VERSION ""

NS_ :

BS_:

BU_: CLU CGW BCW MDPS SCC AVM FCA ESC

BO_ 3221225472 VECTOR__INDEPENDENT_SIG_MSG: 0 Vector__XXX
 SG_ DIAG_RQST : 0|64@1+ (1,0) [0|0] "" Vector__XXX
 SG_ FUN_DIAG_RQST : 0|64@1+ (1,0) [0|0] "" Vector__XXX
 SG_ CF_SWL_Ind : 0|2@1+ (1,0) [0|3] "" Vector__XXX
 SG_ EPB_I_LAMP : 0|4@1+ (1,0) [0|15] "" Vector__XXX
 SG_ EPB_F_LAMP : 0|2@1+ (1,0) [0|3] "" Vector__XXX
 SG_ EPB_ALARM : 0|2@1+ (1,0) [0|3] "" Vector__XXX
 SG_ EPB_CLU : 0|8@1+ (1,0) [0|255] "" Vector__XXX
 SG_ CF_HDA_InfoDisplay : 0|3@1+ (1,0) [0|7] "" Vector__XXX
 SG_ CF_HDA_Mode : 0|2@1+ (1,0) [0|3] "" Vector__XXX
 SG_ CF_HDA_Opt_USM : 0|2@1+ (1,0) [0|3] "" Vector__XXX
 SG_ CF_HDA_AutoSetSpdUpdate : 0|1@1+ (1,0) [0|1] "" Vector__XXX
 SG_ CF_HDA_LFA_Wrn_Snd : 0|1@1+ (1,0) [0|1] "" Vector__XXX
 SG_ CF_HDA_LFA_SymbolState : 0|2@1+ (1,0) [0|3] "" Vector__XXX
 SG_ CF_LFA_Opt_USM : 0|2@1+ (1,0) [0|3] "" Vector__XXX
 SG_ AutoSetSpdEnable : 0|1@1+ (1,0) [0|1] "" Vector__XXX
 SG_ CF_LKA_LaneRecogState : 0|2@1+ (1,0) [0|3] "" Vector__XXX
 SG_ CF_LKA_SysState : 0|4@1+ (1,0) [0|15] "" Vector__XXX
 SG_ CF_LKA_SysWarning : 0|4@1+ (1,0) [0|15] "" Vector__XXX
 SG_ CF_LKA_LHWarning : 0|2@1+ (1,0) [0|3] "" Vector__XXX
 SG_ CF_LKA_RHWarning : 0|2@1+ (1,0) [0|3] "" Vector__XXX
 SG_ CF_HBA_Lamp : 0|1@1+ (1,0) [0|1] "" Vector__XXX
 SG_ CF_HBA_SysState : 0|3@1+ (1,0) [0|7] "" Vector__XXX
 SG_ CF_LKA_USM_Mode : 0|2@1+ (1,0) [0|3] "" Vector__XXX
 SG_ CF_LKA_SymbolState : 0|3@1+ (1,0) [0|7] "" Vector__XXX
 SG_ CF_LKA_Opt_USM : 0|3@1+ (1,0) [0|7] "" Vector__XXX
 SG_ CF_FCA_LO_Warning : 0|2@1+ (1,0) [0|3] "" Vector__XXX
 SG_ CF_HBA_Opt_USM : 0|2@1+ (1,0) [0|3] "" Vector__XXX
 SG_ CF_DAW_Status : 0|4@1+ (1,0) [0|15] "" Vector__XXX
 SG_ CF_DAW_TimeReset : 0|1@1+ (1,0) [0|1] "" Vector__XXX
 SG_ CF_DAW_Opt_USM_NEW : 0|2@1+ (1,0) [0|3] "" Vector__XXX
 SG_ CF_DAW_Warn : 0|2@1+ (1,0) [0|3] "" Vector__XXX
 SG_ CF_LeadVehDptAlert_Display : 0|2@1+ (1,0) [0|3] "" Vector__XXX
 SG_ CF_ISLW_Opt_USM : 0|2@1+ (1,0) [0|3] "" Vector__XXX
 SG_ CF_LeadVehDptAlert_USM : 0|2@1+ (1,0) [0|3] "" Vector__XXX
 SG_ POS_FL_W_LAMP : 0|1@1+ (1,0) [0|1] "" Vector__XXX
 SG_ POS_FR_W_LAMP : 0|1@1+ (1,0) [0|1] "" Vector__XXX
 SG_ POS_RL_W_LAMP : 0|1@1+ (1,0) [0|1] "" Vector__XXX
 SG_ POS_RR_W_LAMP : 0|1@1+ (1,0) [0|1] "" Vector__XXX
 SG_ STATUS_TPMS : 0|3@1+ (1,0) [0|7] "" Vector__XXX
 SG_ UNIT : 0|2@1+ (1,0) [0|3] "" Vector__XXX
 SG_ PRESSURE_FL : 0|8@1+ (1,0) [0|255] "" Vector__XXX
 SG_ PRESSURE_FR : 0|8@1+ (1,0) [0|255] "" Vector__XXX
 SG_ PRESSURE_RL : 0|8@1+ (1,0) [0|255] "" Vector__XXX
 SG_ PRESSURE_RR : 0|8@1+ (1,0) [0|255] "" Vector__XXX
 SG_ TPMS_W_LAMP : 0|2@1+ (1,0) [0|3] "" Vector__XXX
 SG_ TREAD_W_LAMP : 0|2@1+ (1,0) [0|3] "" Vector__XXX

BO_ 1998 DIAG_RSP: 8 CLU
 SG_ DIAG_RSP : 0|64@1+ (1,0) [0|0] "" Vector__XXX

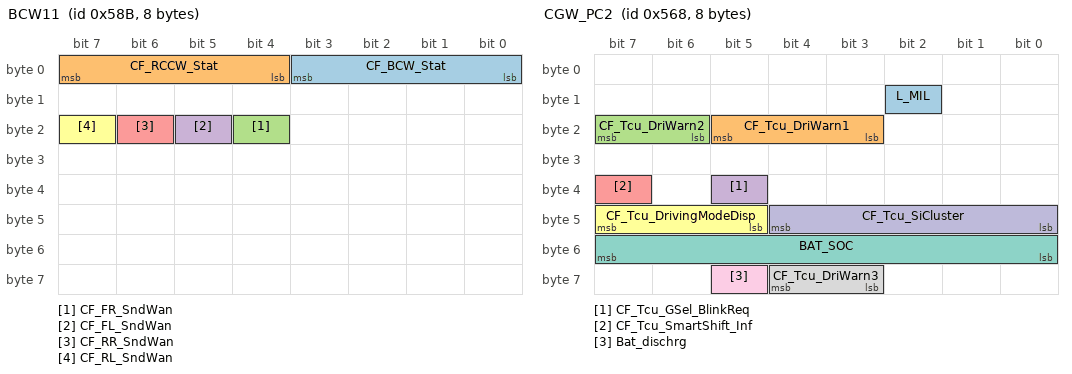
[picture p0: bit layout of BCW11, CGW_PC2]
BO_ 1419 BCW11: 8 BCW
 SG_ CF_BCW_Stat : 0|4@1+ (1,0) [0|15] ""  CGW,CLU
 SG_ CF_RCCW_Stat : 4|4@1+ (1,0) [0|15] ""  CGW,CLU
 SG_ CF_FR_SndWan : 20|1@1+ (1,0) [0|1] ""  CGW,CLU
 SG_ CF_FL_SndWan : 21|1@1+ (1,0) [0|1] ""  CGW,CLU
 SG_ CF_RR_SndWan : 22|1@1+ (1,0) [0|1] ""  CGW,CLU
 SG_ CF_RL_SndWan : 23|1@1+ (1,0) [0|1] ""  CGW,CLU

BO_ 1164 BCW12: 8 BCW
 SG_ CF_BCW_DrvSetState : 5|3@1+ (1,0) [0|7] ""  CGW,CLU

BO_ 1107 CGW_PC1: 5 CGW
 SG_ CR_Fatc_OutTempSns : 16|8@1+ (0.5,0) [-40|60] ""  CLU
 SG_ CR_Fatc_OutTemp : 8|8@1+ (0.5,0) [-40|60] ""  CLU

BO_ 1384 CGW_PC2: 8 CGW
 SG_ L_MIL : 10|1@1+ (1,0) [0|1] ""  CLU
 SG_ CF_Tcu_DriWarn1 : 19|3@1+ (1,0) [0|7] ""  CLU
 SG_ CF_Tcu_DriWarn2 : 22|2@1+ (1,0) [0|3] ""  CLU
 SG_ CF_Tcu_GSel_BlinkReq : 37|1@1+ (1,0) [0|1] ""  CLU
 SG_ CF_Tcu_SmartShift_Inf : 39|1@1+ (1,0) [0|1] ""  CLU
 SG_ CF_Tcu_DrivingModeDisp : 45|3@1+ (1,0) [0|7] ""  CLU
 SG_ BAT_SOC : 48|8@1+ (1,0) [0|100] ""  CLU
 SG_ CF_Tcu_DriWarn3 : 59|2@1+ (1,0) [0|3] ""  CLU
 SG_ Bat_dischrg : 61|1@1+ (1,0) [0|1] ""  CLU
 SG_ CF_Tcu_SiCluster : 40|5@1+ (1,0) [0|31] ""  CLU

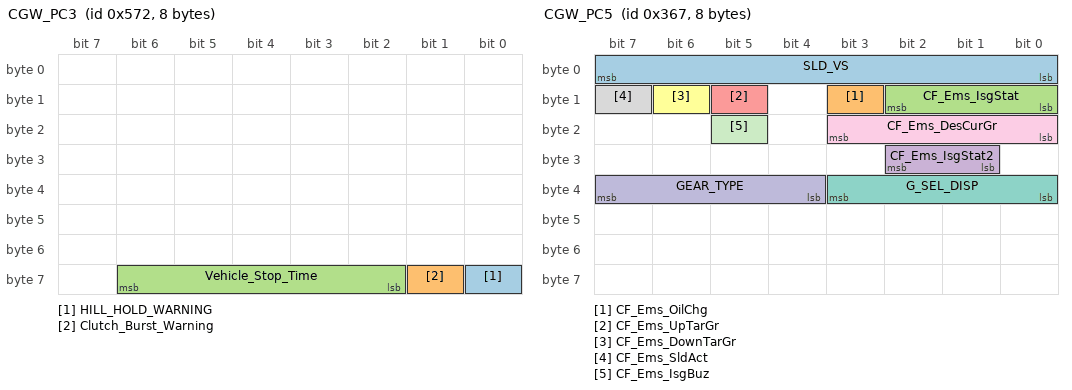
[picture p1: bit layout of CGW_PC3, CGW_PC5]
BO_ 1394 CGW_PC3: 8 CGW
 SG_ HILL_HOLD_WARNING : 56|1@1+ (1,0) [0|1] ""  CLU
 SG_ Clutch_Burst_Warning : 57|1@1+ (1,0) [0|1] ""  CLU
 SG_ Vehicle_Stop_Time : 58|5@1+ (1,0) [0|0] ""  CLU

BO_ 870 CGW_PC4: 7 CGW
 SG_ N : 8|16@1+ (0.25,0) [0|16383.75] ""  CLU
 SG_ F_N_ENG : 49|1@1+ (1,0) [0|1] ""  CLU

BO_ 871 CGW_PC5: 8 CGW
 SG_ SLD_VS : 0|8@1+ (1,0) [0|255] ""  CLU
 SG_ CF_Ems_OilChg : 11|1@1+ (1,0) [0|1] ""  CLU
 SG_ CF_Ems_IsgStat : 8|3@1+ (1,0) [0|7] ""  CLU,MDPS,SCC
 SG_ CF_Ems_IsgStat2 : 25|2@1+ (2,0) [0|3] ""  CLU
 SG_ CF_Ems_UpTarGr : 13|1@1+ (1,0) [0|1] ""  CLU
 SG_ CF_Ems_DownTarGr : 14|1@1+ (1,0) [0|1] ""  CLU
 SG_ G_SEL_DISP : 32|4@1+ (1,0) [0|15] ""  AVM,BCW,CLU,FCA,MDPS,SCC
 SG_ CF_Ems_SldAct : 15|1@1+ (1,0) [0|1] ""  CLU,SCC
 SG_ CF_Ems_DesCurGr : 16|4@1+ (1,0) [0|15] ""  CLU
 SG_ GEAR_TYPE : 36|4@1+ (1,0) [0|15] ""  CLU
 SG_ CF_Ems_IsgBuz : 21|1@1+ (1,0) [0|1] ""  CLU

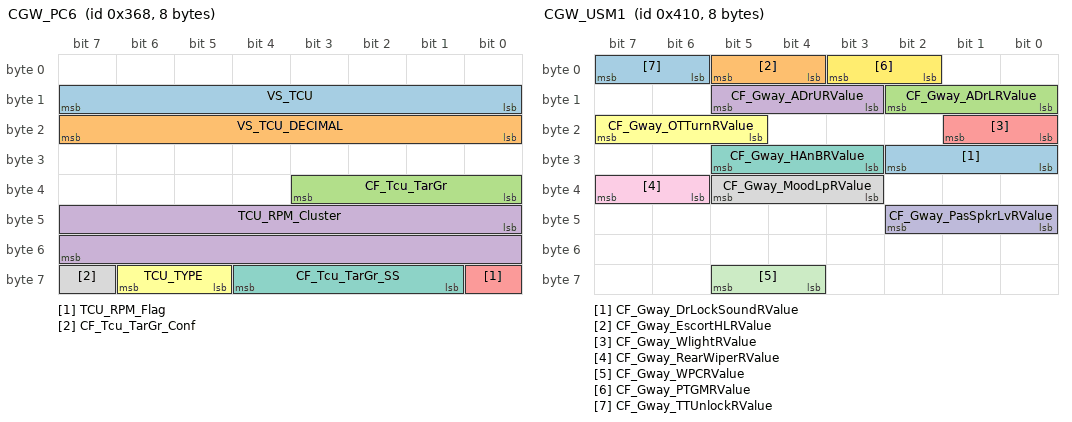
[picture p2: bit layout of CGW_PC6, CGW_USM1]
BO_ 872 CGW_PC6: 8 CGW
 SG_ VS_TCU : 8|8@1+ (1,0) [0|254] ""  CLU
 SG_ VS_TCU_DECIMAL : 16|8@1+ (0.0078125,0) [0|0.9921875] ""  CLU
 SG_ CF_Tcu_TarGr : 32|4@1+ (1,0) [0|15] ""  CLU
 SG_ TCU_RPM_Cluster : 40|16@1+ (0.25,0) [0|16383.5] ""  CLU
 SG_ TCU_RPM_Flag : 56|1@1+ (1,0) [0|0] ""  CLU
 SG_ TCU_TYPE : 61|2@1+ (1,0) [0|3] ""  CLU
 SG_ CF_Tcu_TarGr_SS : 57|4@1+ (1,0) [0|15] ""  CLU
 SG_ CF_Tcu_TarGr_Conf : 63|1@1+ (1,0) [0|0] ""  CLU

BO_ 854 CGW_PC8: 7 CGW
 SG_ FCO : 32|16@1+ (0.128,0) [0|8388.48] ""  CLU

BO_ 576 CGW_PC11: 8 CGW
 SG_ G_SEL_DISP_eClutch : 12|4@1+ (1,0) [0|15] ""  AVM,BCW,CGW,CLU,FCA,MDPS,SCC

BO_ 1225 CGW_PC12: 8 CGW
 SG_ CF_TCU_AvgCltTemp : 0|4@1+ (1,0) [0|15] ""  CLU

BO_ 1040 CGW_USM1: 8 CGW
 SG_ CF_Gway_DrLockSoundRValue : 24|3@1+ (1,0) [0|3] ""  CLU
 SG_ CF_Gway_EscortHLRValue : 4|2@1+ (1,0) [0|3] ""  CLU
 SG_ CF_Gway_ADrLRValue : 8|3@1+ (1,0) [0|7] ""  CLU
 SG_ CF_Gway_ADrURValue : 11|3@1+ (1,0) [0|7] ""  CLU
 SG_ CF_Gway_WlightRValue : 16|2@1+ (1,0) [0|3] ""  CLU
 SG_ CF_Gway_OTTurnRValue : 21|3@1+ (1,0) [0|7] ""  CLU
 SG_ CF_Gway_HAnBRValue : 27|3@1+ (1,0) [0|7] ""  CLU
 SG_ CF_Gway_MoodLpRValue : 35|3@1+ (1,0) [0|7] ""  CLU
 SG_ CF_Gway_RearWiperRValue : 38|2@1+ (1,0) [0|3] ""  CLU
 SG_ CF_Gway_PasSpkrLvRValue : 40|3@1+ (1,0) [0|7] ""  CLU
 SG_ CF_Gway_WPCRValue : 60|2@1+ (1,0) [0|3] ""  CLU
 SG_ CF_Gway_PTGMRValue : 2|2@1+ (1,0) [0|3] ""  CLU
 SG_ CF_Gway_TTUnlockRValue : 6|2@1+ (1,0) [0|3] ""  CLU

BO_ 1042 CGW_USM2: 8 CGW
 SG_ CF_Gway_AFoldRValue : 0|2@1+ (1,0) [0|3] ""  CLU
 SG_ CF_Gway_WALRValue : 46|2@1+ (1,0) [0|3] ""  CLU

BO_ 1345 CGW1: 8 CGW
 SG_ CF_Gway_IGNSw : 0|3@1+ (1,0) [0|7] ""  CLU
 SG_ CF_Gway_RKECmd : 3|3@1+ (1,0) [0|7] ""  CLU
 SG_ CF_Gway_DrvDrSw : 8|2@1+ (1,0) [0|3] ""  CLU
 SG_ CF_Gway_TrunkTgSw : 12|2@1+ (1,0) [0|3] ""  CLU
 SG_ CF_Gway_SMKOption : 16|1@1+ (1,0) [0|1] ""  CLU
 SG_ CF_Gway_HoodSw : 17|2@1+ (1,0) [0|3] ""  CLU
 SG_ CF_Gway_TurnSigLh : 19|2@1+ (1,0) [0|3] ""  CLU
 SG_ CF_Gway_WiperIntT : 21|3@1+ (1,0) [0|7] ""  CLU
 SG_ CF_Gway_HeadLampLow : 31|1@1+ (1,0) [0|1] ""  CLU
 SG_ CF_Gway_HeadLampHigh : 32|1@1+ (1,0) [0|1] ""  CLU
 SG_ CF_Gway_AstDrSw : 35|1@1+ (1,0) [0|1] ""  CLU
 SG_ CF_Gway_LightSwState : 38|2@1+ (1,0) [0|3] ""  CLU
 SG_ CF_Gway_Frt_Fog_Act : 40|1@1+ (1,0) [0|1] ""  CLU
 SG_ CF_Gway_DriveTypeOption : 43|1@1+ (1,0) [0|1] ""  CLU
 SG_ CF_Gway_PassiveAccessLock : 45|2@1+ (1,0) [0|7] ""  CLU
 SG_ CF_Gway_PassiveAccessUnlock : 48|2@1+ (1,0) [0|7] ""  CLU
 SG_ CF_Gway_InhibitRMT : 54|2@1+ (1,0) [0|3] ""  CLU
 SG_ CF_Gway_RainSnsOption : 56|1@1+ (1,0) [0|1] ""  CLU
 SG_ C_SunRoofOpenState : 57|1@1+ (1,0) [0|1] ""  CLU
 SG_ CF_Gway_ParkBrakeSw : 60|2@1+ (1,0) [0|3] ""  CLU
 SG_ CF_Gway_TurnSigRh : 62|2@1+ (1,0) [0|3] ""  CLU

BO_ 1363 CGW2: 8 CGW
 SG_ CF_Gway_ExtTailAct : 8|2@1+ (1,0) [0|3] ""  CLU
 SG_ CF_Gway_AutoLightValue : 16|1@1+ (1,0) [0|1] ""  CLU
 SG_ CF_Gway_BrakeFluidSw : 17|1@1+ (1,0) [0|1] ""  CLU
 SG_ CF_Gway_ICUPowerAutoCutMode : 18|2@1+ (1,0) [0|3] ""  CLU
 SG_ CF_Gway_AvTail : 20|1@1+ (1,0) [0|1] ""  CLU
 SG_ CF_Gway_RearFogAct : 21|1@1+ (1,0) [0|1] ""  CLU
 SG_ CF_Gway_RRDrSw : 23|1@1+ (1,0) [0|1] ""  CLU
 SG_ CF_Gway_RLDrSw : 24|1@1+ (1,0) [0|1] ""  CLU
 SG_ CF_Gway_ESCLFailWarn : 35|1@1+ (1,0) [0|1] ""  CLU
 SG_ CF_Gway_ESCLNotLockedWarn : 36|1@1+ (1,0) [0|1] ""  CLU
 SG_ CF_Gway_ESCLNotUnlockWarn : 37|1@1+ (1,0) [0|1] ""  CLU
 SG_ CF_Gway_IDoutWarn : 38|1@1+ (1,0) [0|1] ""  CLU
 SG_ CF_Gway_ImmoLp : 40|1@1+ (1,0) [0|3] ""  CLU
 SG_ CF_Gway_VehicleNotPWarn : 44|1@1+ (1,0) [0|1] ""  CLU
 SG_ CF_Gway_DeactivationWarn : 45|1@1+ (1,0) [0|1] ""  CLU
 SG_ CF_Gway_KeyBATDischargeWarn : 46|1@1+ (1,0) [0|1] ""  CLU
 SG_ CF_Gway_SSBWarn : 47|1@1+ (1,0) [0|1] ""  CLU
 SG_ CF_Gway_SMKRKECmd : 51|3@1+ (1,0) [0|7] ""  CLU
 SG_ CF_Gway_KeyoutLp : 56|1@1+ (1,0) [0|1] ""  CLU
 SG_ CF_Gway_SMKDispWarn : 57|4@1+ (1,0) [0|15] ""  CLU
 SG_ CF_Gway_WngBuz : 61|3@1+ (1,0) [0|7] ""  CLU

BO_ 1312 CGW3: 8 CGW
 SG_ CF_Gway_AccINDforCLU : 60|1@1+ (1,0) [0|1] ""  CLU

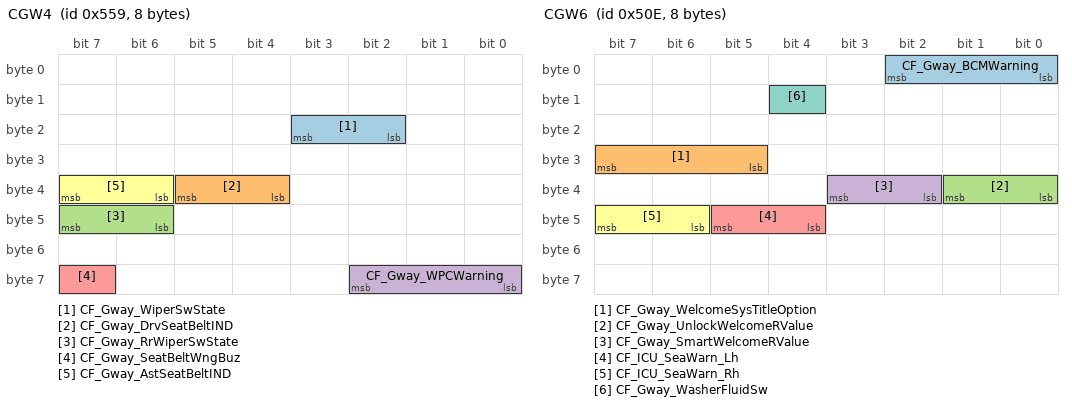
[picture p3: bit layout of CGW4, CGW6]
BO_ 1369 CGW4: 8 CGW
 SG_ CF_Gway_WiperSwState : 18|2@1+ (1,0) [0|3] ""  CLU
 SG_ CF_Gway_DrvSeatBeltIND : 36|2@1+ (1,0) [0|3] ""  CLU
 SG_ CF_Gway_RrWiperSwState : 46|2@1+ (1,0) [0|3] ""  CLU
 SG_ CF_Gway_WPCWarning : 56|3@1+ (1,0) [0|7] ""  CLU
 SG_ CF_Gway_SeatBeltWngBuz : 63|1@1+ (1,0) [0|1] ""  CLU
 SG_ CF_Gway_AstSeatBeltIND : 38|2@1+ (1,0) [0|3] ""  CLU

BO_ 127 CGW5: 8 CGW
 SG_ C_StopLampLhOpenSts : 0|1@1+ (1,0) [0|1] ""  CLU
 SG_ C_StopLampRhOpenSts : 1|1@1+ (1,0) [0|1] ""  CLU
 SG_ C_HMSLOpenSts : 2|1@1+ (1,0) [0|1] ""  CLU
 SG_ C_HLampLowLhOpenSts : 3|1@1+ (1,0) [0|1] ""  CLU
 SG_ C_HLampLowRhOpenSts : 4|1@1+ (1,0) [0|1] ""  CLU
 SG_ C_HLampHighLhOpenSts : 5|1@1+ (1,0) [0|1] ""  CLU
 SG_ C_HLampHighRhOpenSts : 6|1@1+ (1,0) [0|1] ""  CLU
 SG_ C_DRLLampLhOpenSts : 7|1@1+ (1,0) [0|1] ""  CLU
 SG_ C_DRLLampRhOpenSts : 8|1@1+ (1,0) [0|1] ""  CLU
 SG_ C_RearFOGLhOpenSts : 9|1@1+ (1,0) [0|1] ""  CLU
 SG_ C_RearFOGRhOpenSts : 10|1@1+ (1,0) [0|1] ""  CLU
 SG_ C_FrontFOGLhOpenSts : 11|1@1+ (1,0) [0|1] ""  CLU
 SG_ C_FrontFOGRhOpenSts : 12|1@1+ (1,0) [0|1] ""  CLU
 SG_ C_RearTSIGLhOpenSts : 17|1@1+ (1,0) [0|1] ""  CLU
 SG_ C_RearTSIGRhOpenSts : 18|1@1+ (1,0) [0|1] ""  CLU
 SG_ C_FrontTSIGLhOpenSts : 19|1@1+ (1,0) [0|1] ""  CLU
 SG_ C_FrontTSIGRhOpenSts : 20|1@1+ (1,0) [0|1] ""  CLU
 SG_ C_SBendingLhOpenSts : 21|1@1+ (1,0) [0|1] ""  CLU
 SG_ C_SBendingRhOpenSts : 22|1@1+ (1,0) [0|1] ""  CLU
 SG_ C_HLampBifuncLhOpenSts : 25|1@1+ (1,0) [0|1] ""  CLU
 SG_ C_HLampBifuncRhOpenSts : 26|1@1+ (1,0) [0|1] ""  CLU
 SG_ CF_Afs_LedHLStat : 30|2@1+ (1,0) [0|3] ""  CLU
 SG_ C_FrontEXTTailLhOpenSts : 15|1@1+ (1,0) [0|1] ""  CLU
 SG_ C_FrontEXTTailRhOpenSts : 16|1@1+ (1,0) [0|1] ""  CLU
 SG_ C_RearEXTTailLhOpenSts : 13|1@1+ (1,0) [0|1] ""  CLU
 SG_ C_RearEXTTailRhOpenSts : 14|1@1+ (1,0) [0|1] ""  CLU
 SG_ C_LicensePlateLhOpenSts : 23|1@1+ (1,0) [0|1] ""  CLU
 SG_ C_LicensePlateRhOpenSts : 24|1@1+ (1,0) [0|1] ""  CLU
 SG_ C_FrontFOGCorneringLpRhOpenSts : 28|1@1+ (1,0) [0|1] ""  CLU
 SG_ C_FrontFOGCorneringLpLhOpenSts : 29|1@1+ (1,0) [0|1] ""  CLU
 SG_ CF_Gway_MoodLpColorRValue : 56|4@1+ (1,0) [0|15] ""  CLU
 SG_ CF_Gway_MoodLpBrightRValue : 60|3@1+ (1,0) [0|7] ""  CLU

BO_ 1294 CGW6: 8 CGW
 SG_ CF_Gway_BCMWarning : 0|3@1+ (1,0) [0|7] ""  CLU
 SG_ CF_Gway_WelcomeSysTitleOption : 29|3@1+ (1,0) [0|0] ""  CLU
 SG_ CF_Gway_UnlockWelcomeRValue : 32|2@1+ (1,0) [0|0] ""  CLU
 SG_ CF_Gway_SmartWelcomeRValue : 34|2@1+ (1,0) [0|0] ""  CLU
 SG_ CF_ICU_SeaWarn_Lh : 44|2@1+ (1,0) [0|0] ""  CLU
 SG_ CF_ICU_SeaWarn_Rh : 46|2@1+ (1,0) [0|0] ""  CLU
 SG_ CF_Gway_WasherFluidSw : 12|1@1+ (1,0) [0|1] ""  CLU

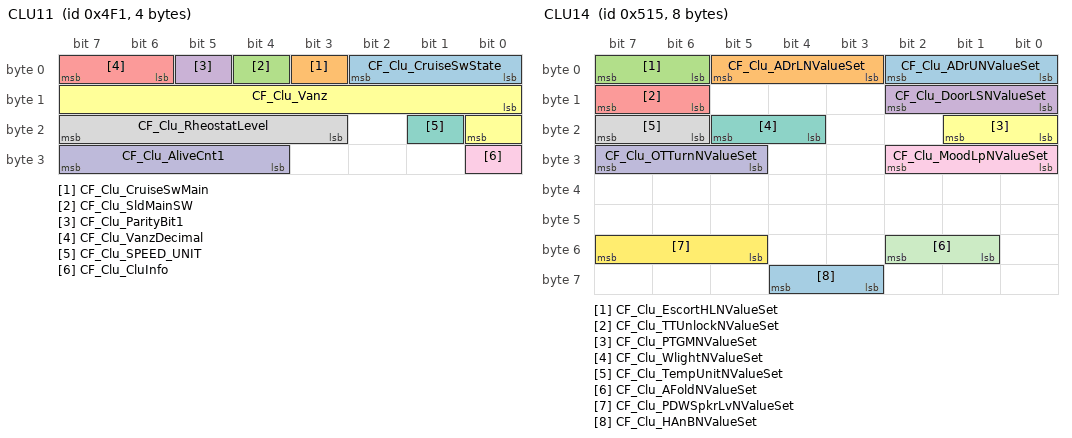
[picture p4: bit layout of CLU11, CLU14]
BO_ 1265 CLU11: 4 CLU
 SG_ CF_Clu_CruiseSwState : 0|3@1+ (1,0) [0|7] ""  CGW
 SG_ CF_Clu_CruiseSwMain : 3|1@1+ (1,0) [0|1] ""  CGW
 SG_ CF_Clu_SldMainSW : 4|1@1+ (1,0) [0|1] ""  CGW,SCC
 SG_ CF_Clu_ParityBit1 : 5|1@1+ (1,0) [0|1] ""  CGW
 SG_ CF_Clu_VanzDecimal : 6|2@1+ (0.125,0) [0|0.375] "" Vector__XXX
 SG_ CF_Clu_Vanz : 8|9@1+ (0.5,0) [0|255.5] ""  CGW
 SG_ CF_Clu_SPEED_UNIT : 17|1@1+ (1,0) [0|1] ""  CGW,ESC
 SG_ CF_Clu_RheostatLevel : 19|5@1+ (1,0) [0|31] ""  CGW
 SG_ CF_Clu_CluInfo : 24|1@1+ (1,0) [0|1] "" Vector__XXX
 SG_ CF_Clu_AliveCnt1 : 28|4@1+ (1,0) [0|15] ""  CGW

BO_ 1456 CLU12: 4 CLU
 SG_ CF_Clu_Odometer : 0|24@1+ (0.1,0) [0|1677721.4] ""  CGW

BO_ 1292 CLU13: 8 CLU
 SG_ CF_Clu_LowfuelWarn : 0|2@1+ (1,0) [0|3] ""  CGW
 SG_ CF_Clu_RefDetMod : 2|1@1+ (1,0) [0|1] ""  CGW
 SG_ CF_Clu_AvgFCU : 3|2@1+ (1,0) [0|3] "" Vector__XXX
 SG_ CF_Clu_AvgFCI : 6|10@1+ (0.1,0) [0|102.2] "" Vector__XXX
 SG_ CF_Clu_DrivingModeSwi : 16|2@1+ (1,0) [0|3] ""  CGW,ESC
 SG_ CF_Clu_TerrainModeSw : 18|3@1+ (1,0) [0|7] ""  CGW,ESC
 SG_ CF_Clu_GLOW_Stat : 21|2@1+ (1,0) [0|3] "" Vector__XXX
 SG_ CF_Clu_DTE : 24|10@1+ (1,0) [0|1023] ""  CGW
 SG_ CF_Clu_TripUnit : 34|2@1+ (1,0) [0|3] ""  CGW
 SG_ CF_Clu_SWL_Stat : 36|3@1+ (1,0) [0|7] "" Vector__XXX
 SG_ CF_Clu_DrivinglampStat : 44|3@1+ (1,0) [0|7] ""  CGW,ESC
 SG_ CF_Clu_RefuelWarn : 53|2@1+ (1,0) [0|3] "" Vector__XXX
 SG_ CF_Clu_IceWarnIndStat : 55|1@1+ (1,0) [0|1] "" Vector__XXX
 SG_ CF_Clu_ClusterUSM : 57|2@1+ (1,0) [0|0] ""  CGW
 SG_ CF_Clu_AltLStatus : 59|1@1+ (1,0) [0|1] "" Vector__XXX
 SG_ CF_Clu_AliveCnt2 : 60|4@1+ (1,0) [0|15] "" Vector__XXX
 SG_ CF_Clu_DAWLastBreakTime : 49|4@1+ (1,0) [0|15] ""  CGW

BO_ 1301 CLU14: 8 CLU
 SG_ CF_Clu_ADrUNValueSet : 0|3@1+ (1,0) [0|7] ""  CGW
 SG_ CF_Clu_ADrLNValueSet : 3|3@1+ (1,0) [0|7] ""  CGW
 SG_ CF_Clu_EscortHLNValueSet : 6|2@1+ (1,0) [0|3] ""  CGW
 SG_ CF_Clu_DoorLSNValueSet : 8|3@1+ (1,0) [0|7] "" Vector__XXX
 SG_ CF_Clu_TTUnlockNValueSet : 14|2@1+ (1,0) [0|3] "" Vector__XXX
 SG_ CF_Clu_PTGMNValueSet : 16|2@1+ (1,0) [0|3] "" Vector__XXX
 SG_ CF_Clu_WlightNValueSet : 20|2@1+ (1,0) [0|3] "" Vector__XXX
 SG_ CF_Clu_TempUnitNValueSet : 22|2@1+ (1,0) [0|3] ""  CGW
 SG_ CF_Clu_MoodLpNValueSet : 24|3@1+ (1,0) [0|7] ""  CGW
 SG_ CF_Clu_OTTurnNValueSet : 29|3@1+ (1,0) [0|7] ""  CGW
 SG_ CF_Clu_AFoldNValueSet : 49|2@1+ (1,0) [0|3] "" Vector__XXX
 SG_ CF_Clu_PDWSpkrLvNValueSet : 53|3@1+ (1,0) [0|7] ""  CGW
 SG_ CF_Clu_HAnBNValueSet : 59|2@1+ (1,0) [0|3] ""  CGW

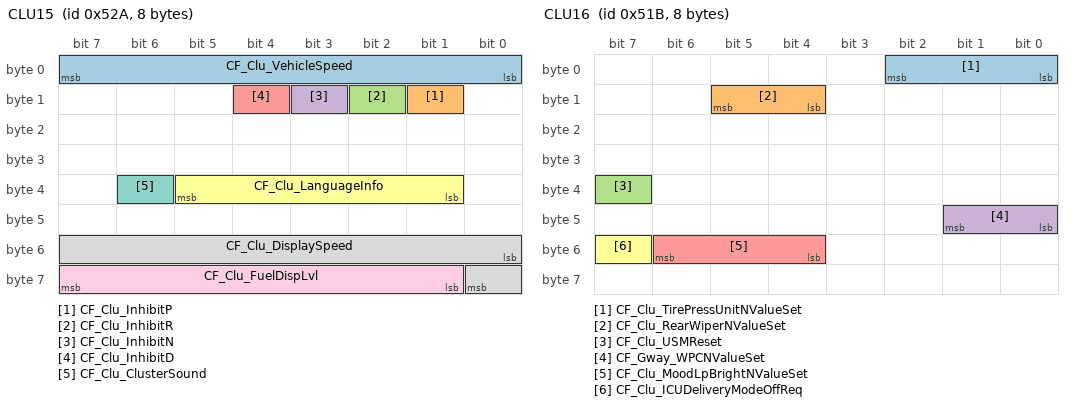
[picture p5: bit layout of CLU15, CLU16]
BO_ 1322 CLU15: 8 CLU
 SG_ CF_Clu_VehicleSpeed : 0|8@1+ (1,0) [0|254] ""  CGW
 SG_ CF_Clu_InhibitP : 9|1@1+ (1,0) [0|1] "" Vector__XXX
 SG_ CF_Clu_InhibitR : 10|1@1+ (1,0) [0|1] "" Vector__XXX
 SG_ CF_Clu_InhibitN : 11|1@1+ (1,0) [0|1] "" Vector__XXX
 SG_ CF_Clu_InhibitD : 12|1@1+ (1,0) [0|1] "" Vector__XXX
 SG_ CF_Clu_LanguageInfo : 33|5@1+ (1,0) [0|31] "" Vector__XXX
 SG_ CF_Clu_ClusterSound : 38|1@1- (1,0) [0|0] ""  CGW
 SG_ CF_Clu_DisplaySpeed : 48|9@1+ (1,0) [0|510] ""  CGW
 SG_ CF_Clu_FuelDispLvl : 57|7@1+ (1,0) [0|0] ""  CGW

BO_ 1307 CLU16: 8 CLU
 SG_ CF_Clu_TirePressUnitNValueSet : 0|3@1+ (1,0) [0|7] "" Vector__XXX
 SG_ CF_Clu_RearWiperNValueSet : 12|2@1+ (1,0) [0|3] ""  CGW
 SG_ CF_Clu_USMReset : 39|1@1+ (1,0) [0|1] ""  CGW
 SG_ CF_Gway_WPCNValueSet : 40|2@1+ (1,0) [0|3] ""  CGW
 SG_ CF_Clu_MoodLpBrightNValueSet : 52|3@1+ (1,0) [0|7] ""  CGW
 SG_ CF_Clu_ICUDeliveryModeOffReq : 55|1@1+ (1,0) [0|1] ""  CGW

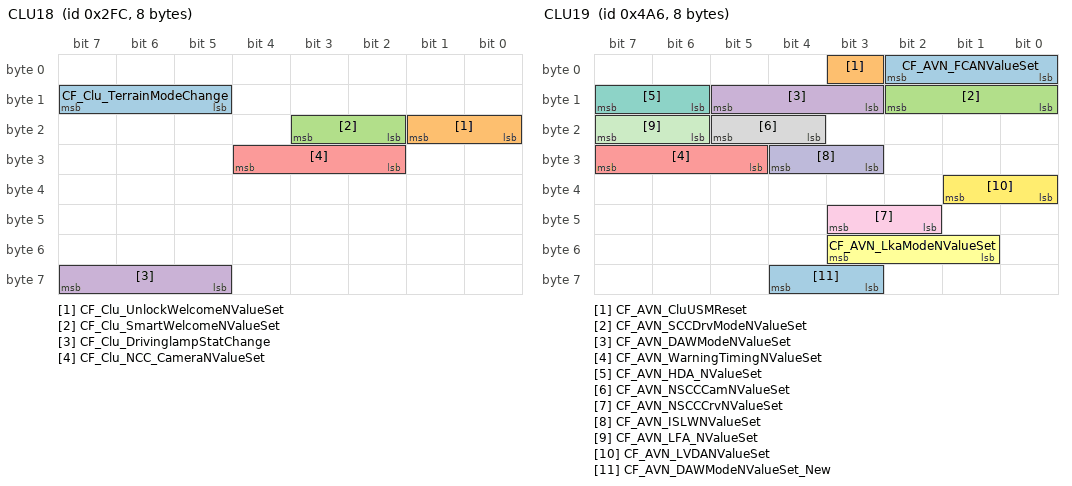
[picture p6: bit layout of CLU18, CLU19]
BO_ 764 CLU18: 8 CLU
 SG_ CF_Clu_TerrainModeChange : 13|3@1+ (1,0) [0|7] ""  CGW
 SG_ CF_Clu_UnlockWelcomeNValueSet : 16|2@1+ (1,0) [0|3] ""  CGW
 SG_ CF_Clu_SmartWelcomeNValueSet : 18|2@1+ (1,0) [0|3] ""  CGW
 SG_ CF_Clu_DrivinglampStatChange : 61|3@1+ (1,0) [0|7] ""  CGW
 SG_ CF_Clu_NCC_CameraNValueSet : 26|3@1+ (1,0) [0|7] ""  CGW

BO_ 1190 CLU19: 8 CLU
 SG_ CF_AVN_FCANValueSet : 0|3@1+ (1,0) [0|7] "" Vector__XXX
 SG_ CF_AVN_CluUSMReset : 3|1@1+ (1,0) [0|1] "" Vector__XXX
 SG_ CF_AVN_SCCDrvModeNValueSet : 8|3@1+ (1,0) [0|7] "" Vector__XXX
 SG_ CF_AVN_DAWModeNValueSet : 11|3@1+ (1,0) [0|7] "" Vector__XXX
 SG_ CF_AVN_WarningTimingNValueSet : 29|3@1+ (1,0) [0|7] "" Vector__XXX
 SG_ CF_AVN_LkaModeNValueSet : 49|3@1+ (1,0) [0|7] "" Vector__XXX
 SG_ CF_AVN_HDA_NValueSet : 14|2@1+ (1,0) [0|3] "" Vector__XXX
 SG_ CF_AVN_NSCCCamNValueSet : 20|2@1+ (1,0) [0|3] ""  SCC
 SG_ CF_AVN_NSCCCrvNValueSet : 42|2@1+ (1,0) [0|3] ""  SCC
 SG_ CF_AVN_ISLWNValueSet : 27|2@1+ (1,0) [0|3] "" Vector__XXX
 SG_ CF_AVN_LFA_NValueSet : 22|2@1+ (1,0) [0|3] "" Vector__XXX
 SG_ CF_AVN_LVDANValueSet : 32|2@1+ (1,0) [0|3] ""  SCC
 SG_ CF_AVN_DAWModeNValueSet_New : 59|2@1+ (1,0) [0|3] "" Vector__XXX

BO_ 1158 CLU20: 8 CLU
 SG_ CF_Clu_WALNValueSet : 58|2@1+ (1,0) [0|3] "" Vector__XXX

BO_ 913 CLU21: 8 CLU
 SG_ CF_Clu_PaddUpSwState : 0|1@1+ (1,0) [0|1] "" Vector__XXX
 SG_ CF_Clu_PaddDownSwState : 1|1@1+ (1,0) [0|1] "" Vector__XXX

BO_ 68 DATC11: 8 CGW
 SG_ CR_Datc_OutTempC : 24|8@1+ (0.5,0) [-41|86.5] ""  CLU
 SG_ CR_Datc_OutTempF : 32|8@1+ (1,0) [-42|213] ""  CLU

BO_ 67 DATC13: 8 CGW
 SG_ CF_Datc_TempDispUnit : 0|2@1+ (1,0) [0|3] ""  CLU

BO_ 809 EMS12: 8 CGW
 SG_ TEMP_ENG : 8|8@1+ (0.75,0) [-48|143.25] ""  CLU

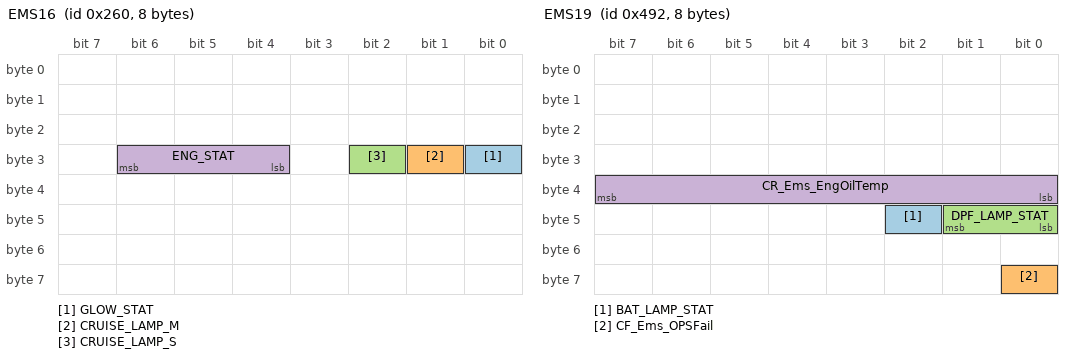
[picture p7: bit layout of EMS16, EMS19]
BO_ 608 EMS16: 8 CGW
 SG_ GLOW_STAT : 24|1@1+ (1,0) [0|1] ""  CLU
 SG_ CRUISE_LAMP_M : 25|1@1+ (1,0) [0|1] ""  CLU
 SG_ CRUISE_LAMP_S : 26|1@1+ (1,0) [0|1] ""  CLU
 SG_ ENG_STAT : 28|3@1+ (1,0) [0|7] ""  CLU,MDPS

BO_ 1170 EMS19: 8 CGW
 SG_ BAT_LAMP_STAT : 42|1@1+ (1,0) [0|1] ""  CLU
 SG_ CF_Ems_OPSFail : 56|1@1+ (1,0) [0|1] ""  CLU
 SG_ DPF_LAMP_STAT : 40|2@1+ (1,0) [0|3] ""  CLU
 SG_ CR_Ems_EngOilTemp : 32|8@1+ (0.75,0) [0|254] ""  CLU

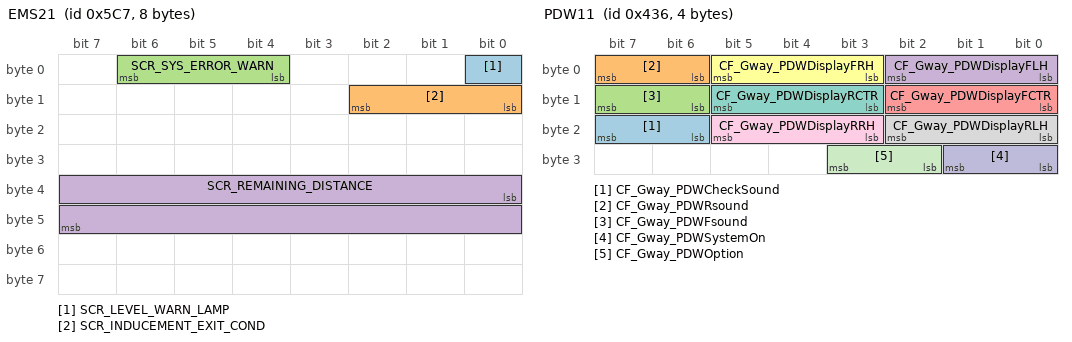
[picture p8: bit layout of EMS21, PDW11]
BO_ 1479 EMS21: 8 CGW
 SG_ SCR_LEVEL_WARN_LAMP : 0|1@1+ (1,0) [0|1] ""  CLU
 SG_ SCR_INDUCEMENT_EXIT_COND : 8|3@1+ (1,0) [0|7] ""  CLU
 SG_ SCR_SYS_ERROR_WARN : 4|3@1+ (1,0) [0|7] ""  CLU
 SG_ SCR_REMAINING_DISTANCE : 32|16@1+ (1,0) [0|25000] ""  CLU

BO_ 1155 FCA12: 8 FCA
 SG_ FCA_DrvSetState : 3|3@1+ (1,0) [0|7] ""  CGW,CLU
 SG_ FCA_USM : 0|3@1+ (1,0) [0|7] ""  CGW,CLU

BO_ 897 MDPS11: 8 MDPS
 SG_ CF_Mdps_WLmp : 0|2@1+ (1,0) [0|3] ""  CGW,CLU,ESC

BO_ 1078 PDW11: 4 CGW
 SG_ CF_Gway_PDWCheckSound : 22|2@1+ (1,0) [0|3] ""  CLU
 SG_ CF_Gway_PDWRsound : 6|2@1+ (1,0) [0|3] ""  CLU
 SG_ CF_Gway_PDWFsound : 14|2@1+ (1,0) [0|3] ""  CLU
 SG_ CF_Gway_PDWDisplayFLH : 0|3@1+ (1,0) [0|7] ""  AVM,CLU
 SG_ CF_Gway_PDWDisplayFCTR : 8|3@1+ (1,0) [0|7] ""  AVM,CLU
 SG_ CF_Gway_PDWDisplayFRH : 3|3@1+ (1,0) [0|7] ""  AVM,CLU
 SG_ CF_Gway_PDWDisplayRCTR : 11|3@1+ (1,0) [0|7] ""  AVM,CLU
 SG_ CF_Gway_PDWDisplayRLH : 16|3@1+ (1,0) [0|7] ""  AVM,CLU
 SG_ CF_Gway_PDWDisplayRRH : 19|3@1+ (1,0) [0|7] ""  AVM,CLU
 SG_ CF_Gway_PDWSystemOn : 24|2@1+ (1,0) [0|3] ""  BCW,CLU
 SG_ CF_Gway_PDWOption : 26|2@1+ (1,0) [0|3] ""  CLU

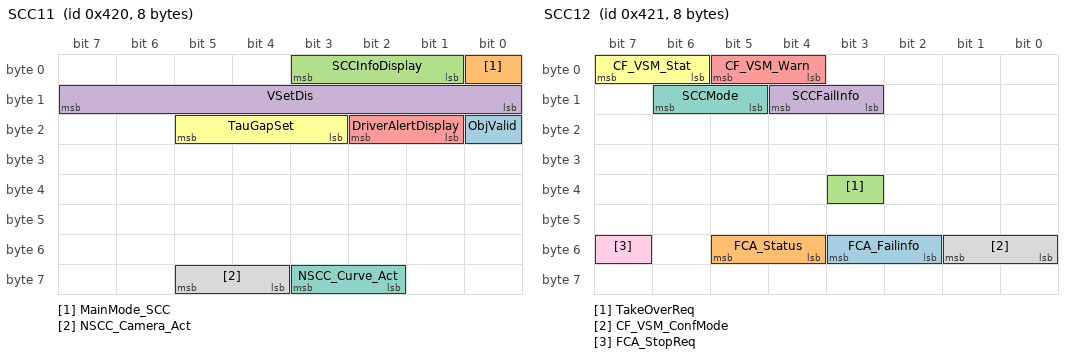
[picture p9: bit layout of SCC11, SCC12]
BO_ 1056 SCC11: 8 SCC
 SG_ ObjValid : 16|1@1+ (1,0) [0|1] ""  CGW,CLU,ESC
 SG_ MainMode_SCC : 0|1@1+ (1,0) [0|1] ""  CGW,CLU,ESC
 SG_ SCCInfoDisplay : 1|3@1+ (1,0) [0|7] ""  CGW,CLU,ESC
 SG_ VSetDis : 8|8@1+ (1,0) [0|255] ""  CGW,CLU,ESC
 SG_ DriverAlertDisplay : 17|2@1+ (1,0) [0|3] ""  CGW,CLU,ESC
 SG_ TauGapSet : 19|3@1+ (1,0) [0|7] ""  CGW,CLU,ESC
 SG_ NSCC_Curve_Act : 58|2@1+ (1,0) [0|3] ""  CGW,CLU
 SG_ NSCC_Camera_Act : 60|2@1+ (1,0) [0|3] ""  CGW,CLU

BO_ 1057 SCC12: 8 SCC
 SG_ FCA_Failinfo : 50|2@1+ (1,0) [0|3] ""  CGW,CLU,ESC
 SG_ FCA_Status : 52|2@1+ (1,0) [0|3] ""  CGW,CLU,ESC
 SG_ TakeOverReq : 35|1@1+ (1,0) [0|1] ""  CGW,CLU,ESC
 SG_ SCCFailInfo : 11|2@1+ (1,0) [0|3] ""  CGW,CLU,ESC
 SG_ CF_VSM_Warn : 4|2@1+ (1,0) [0|3] ""  BCW,CGW,CLU,ESC
 SG_ CF_VSM_Stat : 6|2@1+ (1,0) [0|3] ""  CGW,CLU,ESC
 SG_ SCCMode : 13|2@1+ (1,0) [0|3] ""  CGW,CLU,ESC
 SG_ CF_VSM_ConfMode : 48|2@1+ (1,0) [0|3] ""  CGW,CLU,ESC
 SG_ FCA_StopReq : 55|1@1+ (1,0) [0|1] ""  CGW,CLU,ESC

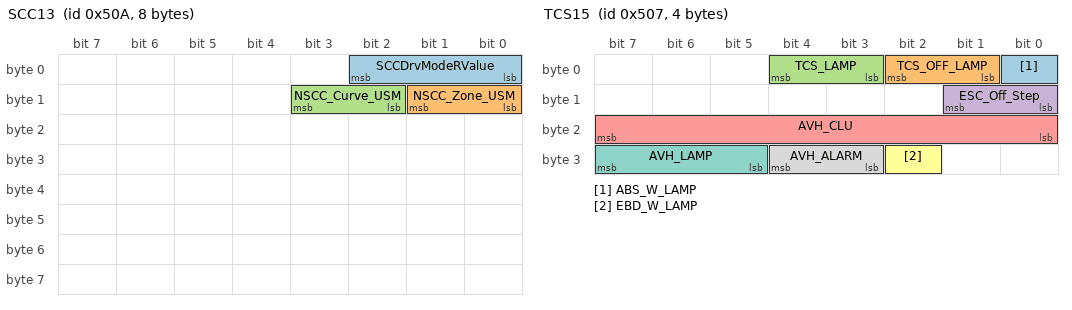
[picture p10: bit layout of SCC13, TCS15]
BO_ 1290 SCC13: 8 SCC
 SG_ SCCDrvModeRValue : 0|3@1+ (1,0) [0|7] ""  CGW,CLU
 SG_ NSCC_Zone_USM : 8|2@1+ (1,0) [0|3] ""  CGW,CLU
 SG_ NSCC_Curve_USM : 10|2@1+ (1,0) [0|3] ""  CGW,CLU

BO_ 905 SCC14: 8 SCC
 SG_ SCCMode2 : 32|3@1+ (1,0) [0|7] ""  CGW,CLU,ESC
 SG_ ObjGap : 56|8@1+ (1,0) [0|255] ""  CGW,CLU,ESC

BO_ 1287 TCS15: 4 ESC
 SG_ ABS_W_LAMP : 0|1@1+ (1,0) [0|1] ""  CGW,CLU
 SG_ TCS_OFF_LAMP : 1|2@1+ (1,0) [0|1] ""  CLU
 SG_ TCS_LAMP : 3|2@1+ (1,0) [0|3] ""  CGW,CLU
 SG_ ESC_Off_Step : 8|2@1+ (1,0) [0|3] ""  CLU
 SG_ AVH_CLU : 16|8@1+ (1,0) [0|255] ""  CLU
 SG_ EBD_W_LAMP : 26|1@1+ (1,0) [0|1] ""  CGW,CLU
 SG_ AVH_LAMP : 29|3@1+ (1,0) [0|7] ""  CGW,CLU
 SG_ AVH_ALARM : 27|2@1+ (1,0) [0|3] ""  CGW,CLU

BO_ 354 TCU_DCT13: 3 CGW
 SG_ Cluster_Engine_RPM : 10|13@1+ (0.9766,0) [0|0] ""  CLU
 SG_ Cluster_Engine_RPM_Flag : 23|1@1+ (1,0) [0|0] ""  CLU

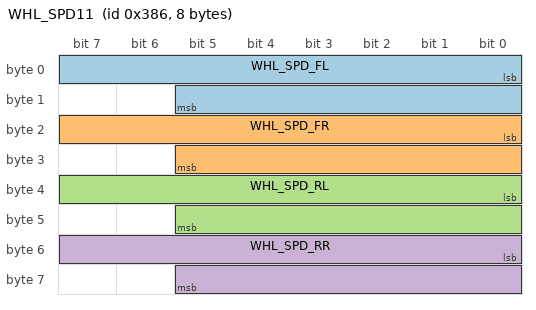
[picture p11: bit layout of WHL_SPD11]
BO_ 902 WHL_SPD11: 8 CGW
 SG_ WHL_SPD_FL : 0|14@1+ (0.03125,0) [0|511.96875] ""  CLU
 SG_ WHL_SPD_FR : 16|14@1+ (0.03125,0) [0|511.96875] ""  CLU
 SG_ WHL_SPD_RL : 32|14@1+ (0.03125,0) [0|511.96875] ""  CLU
 SG_ WHL_SPD_RR : 48|14@1+ (0.03125,0) [0|511.96875] ""  CLU

CM_ BO_ 3221225472 "This is a message for not used signals, created by Vector CANdb++ DBC OLE DB Provider.";
CM_ SG_ 3221225472 CF_LKA_LaneRecogState "This signal is for USM of LCA";
CM_ SG_ 3221225472 CF_DAW_Opt_USM_NEW "This signal is for CLUAVN USM";
CM_ SG_ 1107 CR_Fatc_OutTempSns "PTCAN 4WD11  FATC11 Indirect routing message This  is for the 4WD ECU MAGNA  WIA JV system applied vehicles only";
CM_ SG_ 1107 CR_Fatc_OutTemp "PTCAN 4WD11  FATC11 Indirect routing message This  is for the 4WD ECU MAGNA  WIA JV system applied vehicles only";
CM_ SG_ 1384 L_MIL "PTCAN EMS14EMS15AAF11TCU14PSB11  Indirect routing message In case of Delphi ECU Output period tolerance1ms will be applied to Engine Lamda3";
CM_ SG_ 1384 CF_Tcu_DriWarn1 "PTCAN EMS14EMS15AAF11TCU14PSB11  Indirect routing message In case of Delphi ECU Output period tolerance1ms will be applied to Engine Lamda3";
CM_ SG_ 1384 CF_Tcu_DriWarn2 "PTCAN EMS14EMS15AAF11TCU14PSB11  Indirect routing message In case of Delphi ECU Output period tolerance1ms will be applied to Engine Lamda3";
CM_ SG_ 1384 CF_Tcu_SmartShift_Inf "This signal is for Smart Shift";
CM_ SG_ 1384 CF_Tcu_DrivingModeDisp "This signal is for Smart Shift";
CM_ SG_ 1384 BAT_SOC "This signal is Battery SOC from battery sensor";
CM_ SG_ 1384 CF_Tcu_DriWarn3 "This message is for the DCTDouble Clutch TM system applied vehicles only";
CM_ SG_ 1384 Bat_dischrg "The signal indicates the status of the batt discharge notification flag";
CM_ SG_ 1384 CF_Tcu_SiCluster "This signal is for Smart Shift";
CM_ SG_ 870 N "PTCAN EMS11 Indirect routing message In case of Delphi ECU Output period tolerance1ms will be applied to Engine Lamda3";
CM_ SG_ 870 F_N_ENG "PTCAN EMS11 Indirect routing message In case of Delphi ECU Output period tolerance1ms will be applied to Engine Lamda3";
CM_ SG_ 871 SLD_VS "PTCAN EMS_H12  TCU11 Indirect routing message In case of Delphi ECU Output period tolerance1ms will be applied to Engine Lamda3";
CM_ SG_ 871 CF_Ems_OilChg "PTCAN EMS_H12  TCU11 Indirect routing message In case of Delphi ECU Output period tolerance1ms will be applied to Engine Lamda3";
CM_ SG_ 871 CF_Ems_IsgStat "PTCAN EMS_H12  TCU11 Indirect routing message In case of Delphi ECU Output period tolerance1ms will be applied to Engine Lamda3";
CM_ SG_ 871 CF_Ems_IsgStat2 "PTCAN EMS_H12  TCU11 Indirect routing message In case of Delphi ECU Output period tolerance1ms will be applied to Engine Lamda3";
CM_ SG_ 871 CF_Ems_UpTarGr "PTCAN EMS_H12  TCU11 Indirect routing message In case of Delphi ECU Output period tolerance1ms will be applied to Engine Lamda3";
CM_ SG_ 871 CF_Ems_DownTarGr "PTCAN EMS_H12  TCU11 Indirect routing message In case of Delphi ECU Output period tolerance1ms will be applied to Engine Lamda3";
CM_ SG_ 871 G_SEL_DISP "PTCAN EMS_H12  TCU11 Indirect routing message ";
CM_ SG_ 871 CF_Ems_SldAct "PTCAN EMS_H12  TCU11 Indirect routing message In case of Delphi ECU Output period tolerance1ms will be applied to Engine Lamda3";
CM_ SG_ 871 CF_Ems_DesCurGr "PTCAN EMS_H12  TCU11 Indirect routing message In case of Delphi ECU Output period tolerance1ms will be applied to Engine Lamda3";
CM_ SG_ 871 GEAR_TYPE "PTCAN EMS_H12  TCU11 Indirect routing message ";
CM_ SG_ 871 CF_Ems_IsgBuz "PTCAN EMS_H12  TCU11 Indirect routing message In case of Delphi ECU Output period tolerance1ms will be applied to Engine Lamda3";
CM_ SG_ 872 VS_TCU "PTCAN TCU12  TCU13  Indirect routing message";
CM_ SG_ 872 VS_TCU_DECIMAL "PTCAN TCU12  TCU13  Indirect routing message";
CM_ SG_ 872 CF_Tcu_TarGr "PTCAN TCU12  TCU13  Indirect routing message";
CM_ SG_ 854 FCO "PTCAN LVR11EMS20LPI11TCU_DCT11 Indirect routing message";
CM_ SG_ 1040 CF_Gway_EscortHLRValue "This signal is for IPM Gateway applied vehicles only";
CM_ SG_ 1040 CF_Gway_ADrLRValue "This signal is for IPM Gateway applied vehicles only";
CM_ SG_ 1040 CF_Gway_ADrURValue "This signal is for IPM Gateway applied vehicles only";
CM_ SG_ 1040 CF_Gway_WlightRValue "This signal is for IPM Gateway applied vehicles only";
CM_ SG_ 1040 CF_Gway_TTUnlockRValue "This signal is for IPM Gateway applied vehicles only";
CM_ SG_ 1345 CF_Gway_LightSwState "This signal is for IPM Gateway applied vehicles only";
CM_ SG_ 1345 CF_Gway_DriveTypeOption "This signal is for IPM Gateway applied vehicles only";
CM_ SG_ 1345 CF_Gway_PassiveAccessLock "This signal is for IPM Gateway applied vehicles only";
CM_ SG_ 1345 CF_Gway_PassiveAccessUnlock "This signal is for IPM Gateway applied vehicles only";
CM_ SG_ 1345 CF_Gway_InhibitRMT "This signal is for IPM Gateway applied vehicles only";
CM_ SG_ 1363 CF_Gway_ExtTailAct "This signal is for IPM Gateway applied vehicles only";
CM_ SG_ 1363 CF_Gway_AvTail "This signal is for IPM Gateway applied vehicles only";
CM_ SG_ 1363 CF_Gway_RearFogAct "This signal is for IPM Gateway applied vehicles only";
CM_ SG_ 1363 CF_Gway_RRDrSw "This signal is for IPM Gateway applied vehicles only";
CM_ SG_ 1363 CF_Gway_RLDrSw "This signal is for IPM Gateway applied vehicles only";
CM_ SG_ 1363 CF_Gway_ESCLFailWarn "This signal is for IPM Gateway applied vehicles only";
CM_ SG_ 1363 CF_Gway_ESCLNotLockedWarn "This signal is for IPM Gateway applied vehicles only";
CM_ SG_ 1363 CF_Gway_ESCLNotUnlockWarn "This signal is for IPM Gateway applied vehicles only";
CM_ SG_ 1363 CF_Gway_IDoutWarn "This signal is for IPM Gateway applied vehicles only";
CM_ SG_ 1363 CF_Gway_ImmoLp "This signal is for IPM Gateway applied vehicles only";
CM_ SG_ 1363 CF_Gway_VehicleNotPWarn "This signal is for IPM Gateway applied vehicles only";
CM_ SG_ 1363 CF_Gway_DeactivationWarn "This signal is for IPM Gateway applied vehicles only";
CM_ SG_ 1363 CF_Gway_KeyBATDischargeWarn "This signal is for IPM Gateway applied vehicles only";
CM_ SG_ 1363 CF_Gway_SSBWarn "This signal is for IPM Gateway applied vehicles only";
CM_ SG_ 1363 CF_Gway_SMKRKECmd "This signal is for IPM Gateway applied vehicles only";
CM_ SG_ 1363 CF_Gway_WngBuz "This signal is for IPM Gateway applied vehicles only";
CM_ SG_ 127 CF_Afs_LedHLStat "This signal is for CLU warning of LED HLAMP with the exception of AFS unit";
CM_ SG_ 1265 CF_Clu_RheostatLevel "Rheostat Level from CLUSTER";
CM_ SG_ 1265 CF_Clu_AliveCnt1 "In case of Delphi ECU Output period tolerance1ms will be applied to Engine Lamda3";
CM_ SG_ 1292 CF_Clu_IceWarnIndStat "This signal is for Ice Warning applied regions only";
CM_ SG_ 1292 CF_Clu_AltLStatus "This signal is for IPM Gateway applied vehicles only";
CM_ SG_ 1292 CF_Clu_AliveCnt2 "This signal is for IPM Gateway applied vehicles only";
CM_ SG_ 1292 CF_Clu_DAWLastBreakTime "This signal is used for Driver Attention Warning level calculation by continuous driving time This signal is reset by CF_DAW_TimeReset signal of LKA12 Message";
CM_ SG_ 1301 CF_Clu_WlightNValueSet "Request to set Welcome Light Option";
CM_ SG_ 1301 CF_Clu_MoodLpNValueSet "Request to set Mood Lamp";
CM_ SG_ 1322 CF_Clu_ClusterSound "Sound type of Cluster";
CM_ SG_ 1307 CF_Clu_TirePressUnitNValueSet "Request to set Tire Pressure Unit";
CM_ SG_ 764 CF_Clu_UnlockWelcomeNValueSet "Request to set Door Unlock Welcome System Setting";
CM_ SG_ 764 CF_Clu_SmartWelcomeNValueSet "Request to set Smartkey Welcome System Setting";
CM_ SG_ 68 CR_Datc_OutTempC "This signal is for IPM Gateway applied vehicles only";
CM_ SG_ 68 CR_Datc_OutTempF "This signal is for IPM Gateway applied vehicles only";
CM_ SG_ 67 CF_Datc_TempDispUnit "This signal is for IPM Gateway applied vehicles only";
CM_ SG_ 809 TEMP_ENG "In case of Delphi ECU Output period tolerance1ms will be applied to Engine Lamda3";
CM_ SG_ 608 GLOW_STAT "In case of Delphi ECU Output period tolerance1ms will be applied to Engine Lamda3";
CM_ SG_ 608 CRUISE_LAMP_M "In case of Delphi ECU Output period tolerance1ms will be applied to Engine Lamda3";
CM_ SG_ 608 CRUISE_LAMP_S "In case of Delphi ECU Output period tolerance1ms will be applied to Engine Lamda3";
CM_ SG_ 608 ENG_STAT "In case of Delphi ECU Output period tolerance1ms will be applied to Engine Lamda3";
CM_ SG_ 1479 SCR_LEVEL_WARN_LAMP "SCR Inducement meessage for Passenger car";
CM_ SG_ 1479 SCR_INDUCEMENT_EXIT_COND "SCR Inducement meessage for Passenger car";
CM_ SG_ 1479 SCR_SYS_ERROR_WARN "SCR Inducement meessage for Passenger car";
CM_ SG_ 1479 SCR_REMAINING_DISTANCE "SCR Inducement meessage for Passenger car";
CM_ SG_ 1078 CF_Gway_PDWCheckSound "This signal is for IPM Gateway applied vehicles only";
CM_ SG_ 1078 CF_Gway_PDWRsound "This signal is for IPM Gateway applied vehicles only";
CM_ SG_ 1078 CF_Gway_PDWFsound "This signal is for IPM Gateway applied vehicles only";
CM_ SG_ 1078 CF_Gway_PDWDisplayFLH "This signal is for IPM Gateway applied vehicles only";
CM_ SG_ 1078 CF_Gway_PDWDisplayFCTR "This signal is for IPM Gateway applied vehicles only";
CM_ SG_ 1078 CF_Gway_PDWDisplayFRH "This signal is for IPM Gateway applied vehicles only";
CM_ SG_ 1078 CF_Gway_PDWDisplayRCTR "This signal is for IPM Gateway applied vehicles only";
CM_ SG_ 1078 CF_Gway_PDWDisplayRLH "This signal is for IPM Gateway applied vehicles only";
CM_ SG_ 1078 CF_Gway_PDWDisplayRRH "This signal is for IPM Gateway applied vehicles only";
CM_ SG_ 1056 VSetDis "This signal can be sent in kmh or MPH according to the SPEED_UNIT signal See CLU1 message";
CM_ SG_ 1287 AVH_CLU "This message is for EPB Electric Parking Brake system applied vehicle only";
CM_ SG_ 1287 AVH_LAMP "This message is for EPB Electric Parking Brake system applied vehicle only";
CM_ SG_ 1287 AVH_ALARM "This message is for EPB Electric Parking Brake system applied vehicle only";
CM_ SG_ 354 Cluster_Engine_RPM "Engine RPM only for the display on Cluster";
BA_DEF_ SG_  "Platform" STRING ;
BA_DEF_ SG_  "Validity" ENUM  "B+","ACC","IGN1","IGN2";
BA_DEF_ SG_  "Purpose" ENUM  "<t.b.d.>","Function","Diagnostic","Development","NM";
BA_DEF_ BO_  "RoutingType" ENUM  "<n.a.>","Direct","Indirect";
BA_DEF_ BO_  "GenMsgEVName" STRING ;
BA_DEF_ BO_  "DiagResponse" ENUM  "No","Yes";
BA_DEF_ SG_  "SignalCategory" HEX 10 15;
BA_DEF_ SG_  "GwSigMissingSourceType" ENUM  "Undef","OldValue","DefaultValue","InitialValue";
BA_DEF_ SG_  "GwSigLatencyTime" INT 0 65535;
BA_DEF_ SG_  "GenSigEVName" STRING ;
BA_DEF_ SG_  "GenSigEnvVarType" ENUM  "Int","Float","Undef";
BA_DEF_ BO_  "GenMsgILSupport" ENUM  "No","Yes";
BA_DEF_ BO_  "GenMsgDelayTime" INT 0 20;
BA_DEF_ BO_  "GenMsgCycleTimeFast" INT 0 500;
BA_DEF_ BU_  "NmCAN" INT 1 2;
BA_DEF_ BU_  "ILUsed" ENUM  "No","Yes";
BA_DEF_ BU_  "GenNodSleepTime" INT 1375 1650;
BA_DEF_  "VersionYear" INT 0 9999;
BA_DEF_  "VersionWeek" INT 1 53;
BA_DEF_  "VersionMonth" INT 1 12;
BA_DEF_  "VersionDay" INT 1 31;
BA_DEF_  "SyncJumpWidthMin" INT 1 4;
BA_DEF_  "SyncJumpWidthMax" INT 1 8;
BA_DEF_  "SamplePointMin" INT 55 85;
BA_DEF_  "SamplePointMax" INT 50 85;
BA_DEF_  "NmType" STRING ;
BA_DEF_  "NmMessageCount" INT 0 128;
BA_DEF_  "NmBaseAddress" HEX 0 2047;
BA_DEF_  "Manufacturer" STRING ;
BA_DEF_  "GenNWMTalkNM" STRING ;
BA_DEF_  "GenNWMSleepTime" INT 1375 1650;
BA_DEF_  "GenNWMGotoMode_BusSleep" STRING ;
BA_DEF_  "GenNWMGotoMode_Awake" STRING ;
BA_DEF_  "GenNWMApCanWakeUp" STRING ;
BA_DEF_  "GenNWMApCanSleep" STRING ;
BA_DEF_  "GenNWMApCanOn" STRING ;
BA_DEF_  "GenNWMApCanOff" STRING ;
BA_DEF_  "GenNWMApCanNormal" STRING ;
BA_DEF_  "GenNWMApBusSleep" STRING ;
BA_DEF_  "GenEnvVarPrefix" STRING ;
BA_DEF_  "GenEnvVarEndingSnd" STRING ;
BA_DEF_  "GenEnvVarEndingDsp" STRING ;
BA_DEF_  "Baudrate" INT 50000 1000000;
BA_DEF_ SG_  "GenSigStartValue" INT 0 3000;
BA_DEF_ BO_  "FrameType" INT 0 2;
BA_DEF_ SG_  "GenSigSendType" ENUM  "Cyclic","OnWrite","OnWriteWithRepetition","OnChange","OnChangeWithRepetition","IfActive","IfActiveWithRepetition","NoSigSendType";
BA_DEF_ BO_  "GenMsgCycleTime" INT 0 0;
BA_DEF_ BO_  "GenMsgSendType" ENUM  "Cyclic","Event","not_used","not_used","not_used","Combined(Event/Periodic)","not_used","IfActive","NoMsgSendType";
BA_DEF_  "DBName" STRING ;
BA_DEF_  "BusType" STRING ;
BA_DEF_REL_ BU_SG_REL_  "GenSigTimeoutTime" INT 0 7000;
BA_DEF_DEF_  "Platform" "DIS 2,Premium AVN 2.0,Standard AVN 4.0,Integrated AVN1.0 High,Integrated AVN1.0 Mid,Compact AVN,EU AVN 2.0,D-Audio,UVO3 (D-Audio Kia),Standard Audio 3.0,Standard Audio 4.0,Economic Audio 3.0";
BA_DEF_DEF_  "Validity" "ACC";
BA_DEF_DEF_  "Purpose" "<t.b.d.>";
BA_DEF_DEF_  "RoutingType" "<n.a.>";
BA_DEF_DEF_  "GenMsgEVName" "@Signame";
BA_DEF_DEF_  "DiagResponse" "No";
BA_DEF_DEF_  "SignalCategory" 12;
BA_DEF_DEF_  "GwSigMissingSourceType" "Undef";
BA_DEF_DEF_  "GwSigLatencyTime" 40;
BA_DEF_DEF_  "GenSigEVName" "@Signame";
BA_DEF_DEF_  "GenSigEnvVarType" "Undef";
BA_DEF_DEF_  "GenMsgILSupport" "Yes";
BA_DEF_DEF_  "GenMsgDelayTime" 20;
BA_DEF_DEF_  "GenMsgCycleTimeFast" 40;
BA_DEF_DEF_  "NmCAN" 1;
BA_DEF_DEF_  "ILUsed" "Yes";
BA_DEF_DEF_  "GenNodSleepTime" 1500;
BA_DEF_DEF_  "VersionYear" 2010;
BA_DEF_DEF_  "VersionWeek" 1;
BA_DEF_DEF_  "VersionMonth" 1;
BA_DEF_DEF_  "VersionDay" 1;
BA_DEF_DEF_  "SyncJumpWidthMin" 2;
BA_DEF_DEF_  "SyncJumpWidthMax" 3;
BA_DEF_DEF_  "SamplePointMin" 75;
BA_DEF_DEF_  "SamplePointMax" 82;
BA_DEF_DEF_  "NmType" "Vector";
BA_DEF_DEF_  "NmMessageCount" 128;
BA_DEF_DEF_  "NmBaseAddress" 1024;
BA_DEF_DEF_  "Manufacturer" "HMC";
BA_DEF_DEF_  "GenNWMTalkNM" "TalkNM()";
BA_DEF_DEF_  "GenNWMSleepTime" 1500;
BA_DEF_DEF_  "GenNWMGotoMode_BusSleep" "GotoMode_BusSleep()";
BA_DEF_DEF_  "GenNWMGotoMode_Awake" "GotoMode_Awake()";
BA_DEF_DEF_  "GenNWMApCanWakeUp" "ApplCanWakeUp()";
BA_DEF_DEF_  "GenNWMApCanSleep" "ApplNmCanSleep()";
BA_DEF_DEF_  "GenNWMApCanOn" "ApplCanOnline()";
BA_DEF_DEF_  "GenNWMApCanOff" "ApplCanOffline()";
BA_DEF_DEF_  "GenNWMApCanNormal" "ApplNmCanNormal()";
BA_DEF_DEF_  "GenNWMApBusSleep" "ApplNmCanBusSleep()";
BA_DEF_DEF_  "GenEnvVarPrefix" "Env";
BA_DEF_DEF_  "GenEnvVarEndingSnd" "_";
BA_DEF_DEF_  "GenEnvVarEndingDsp" "Dsp_";
BA_DEF_DEF_  "Baudrate" 500000;
BA_DEF_DEF_  "GenSigStartValue" 0;
BA_DEF_DEF_  "FrameType" 2;
BA_DEF_DEF_  "GenSigSendType" "";
BA_DEF_DEF_  "GenMsgCycleTime" 0;
BA_DEF_DEF_  "GenMsgSendType" "NoMsgSendType";
BA_DEF_DEF_  "DBName" "";
BA_DEF_DEF_  "BusType" "CAN";
BA_DEF_DEF_REL_ "GenSigTimeoutTime" 500;
BA_ "DBName" "TEST";
BA_ "DiagResponse" BO_ 1998 1;
BA_ "GenMsgSendType" BO_ 1998 1;
BA_ "GenMsgCycleTime" BO_ 1419 50;
BA_ "GenMsgSendType" BO_ 1419 0;
BA_ "GenMsgCycleTime" BO_ 1164 200;
BA_ "GenMsgSendType" BO_ 1164 5;
BA_ "GenMsgCycleTime" BO_ 1107 20;
BA_ "GenMsgSendType" BO_ 1107 0;
BA_ "GenMsgCycleTime" BO_ 1384 100;
BA_ "GenMsgSendType" BO_ 1384 0;
BA_ "GenMsgCycleTime" BO_ 1394 200;
BA_ "GenMsgSendType" BO_ 1394 0;
BA_ "GenMsgCycleTime" BO_ 870 10;
BA_ "GenMsgSendType" BO_ 870 0;
BA_ "GenMsgCycleTime" BO_ 871 10;
BA_ "GenMsgSendType" BO_ 871 0;
BA_ "GenMsgCycleTime" BO_ 872 10;
BA_ "GenMsgSendType" BO_ 872 0;
BA_ "GenMsgCycleTime" BO_ 854 10;
BA_ "GenMsgSendType" BO_ 854 0;
BA_ "GenMsgCycleTime" BO_ 576 10;
BA_ "GenMsgSendType" BO_ 576 0;
BA_ "GenMsgCycleTime" BO_ 1225 200;
BA_ "GenMsgSendType" BO_ 1225 0;
BA_ "GenMsgCycleTime" BO_ 1040 200;
BA_ "GenMsgSendType" BO_ 1040 5;
BA_ "GenMsgCycleTime" BO_ 1042 200;
BA_ "GenMsgSendType" BO_ 1042 5;
BA_ "GenMsgCycleTime" BO_ 1345 100;
BA_ "GenMsgSendType" BO_ 1345 5;
BA_ "GenMsgCycleTime" BO_ 1363 200;
BA_ "GenMsgSendType" BO_ 1363 5;
BA_ "GenMsgCycleTime" BO_ 1312 100;
BA_ "GenMsgSendType" BO_ 1312 0;
BA_ "GenMsgCycleTime" BO_ 1369 200;
BA_ "GenMsgSendType" BO_ 1369 5;
BA_ "GenMsgCycleTime" BO_ 127 1000;
BA_ "GenMsgSendType" BO_ 127 5;
BA_ "GenMsgCycleTime" BO_ 1294 200;
BA_ "GenMsgSendType" BO_ 1294 5;
BA_ "GenMsgCycleTime" BO_ 1265 20;
BA_ "GenMsgSendType" BO_ 1265 0;
BA_ "GenMsgCycleTime" BO_ 1456 1000;
BA_ "GenMsgSendType" BO_ 1456 0;
BA_ "GenMsgCycleTime" BO_ 1292 100;
BA_ "GenMsgSendType" BO_ 1292 0;
BA_ "GenMsgSendType" BO_ 1301 1;
BA_ "GenMsgCycleTime" BO_ 1322 200;
BA_ "GenMsgSendType" BO_ 1322 5;
BA_ "GenMsgSendType" BO_ 1307 1;
BA_ "GenMsgSendType" BO_ 764 1;
BA_ "GenMsgSendType" BO_ 1190 1;
BA_ "GenMsgSendType" BO_ 1158 1;
BA_ "GenMsgCycleTime" BO_ 913 20;
BA_ "GenMsgSendType" BO_ 913 0;
BA_ "GenMsgCycleTime" BO_ 68 1000;
BA_ "GenMsgSendType" BO_ 68 5;
BA_ "GenMsgCycleTime" BO_ 67 1000;
BA_ "GenMsgSendType" BO_ 67 5;
BA_ "GenMsgCycleTime" BO_ 809 10;
BA_ "GenMsgSendType" BO_ 809 0;
BA_ "GenMsgCycleTime" BO_ 608 10;
BA_ "GenMsgSendType" BO_ 608 0;
BA_ "GenMsgCycleTime" BO_ 1170 50;
BA_ "GenMsgSendType" BO_ 1170 0;
BA_ "GenMsgCycleTime" BO_ 1479 100;
BA_ "GenMsgSendType" BO_ 1479 0;
BA_ "GenMsgCycleTime" BO_ 1155 200;
BA_ "GenMsgSendType" BO_ 1155 5;
BA_ "GenMsgCycleTime" BO_ 897 20;
BA_ "GenMsgSendType" BO_ 897 0;
BA_ "GenMsgCycleTime" BO_ 1078 50;
BA_ "GenMsgSendType" BO_ 1078 5;
BA_ "GenMsgCycleTime" BO_ 1056 20;
BA_ "GenMsgSendType" BO_ 1056 0;
BA_ "GenMsgCycleTime" BO_ 1057 20;
BA_ "GenMsgSendType" BO_ 1057 0;
BA_ "GenMsgCycleTime" BO_ 1290 200;
BA_ "GenMsgSendType" BO_ 1290 5;
BA_ "GenMsgCycleTime" BO_ 905 20;
BA_ "GenMsgSendType" BO_ 905 0;
BA_ "GenMsgCycleTime" BO_ 1287 100;
BA_ "GenMsgSendType" BO_ 1287 0;
BA_ "GenMsgCycleTime" BO_ 354 10;
BA_ "GenMsgSendType" BO_ 354 0;
BA_ "GenMsgCycleTime" BO_ 902 20;
BA_ "GenMsgSendType" BO_ 902 0;
BA_ "GenSigSendType" SG_ 3221225472 DIAG_RQST 1;
BA_ "GenSigSendType" SG_ 3221225472 FUN_DIAG_RQST 1;
BA_ "GenSigSendType" SG_ 3221225472 CF_SWL_Ind 0;
BA_ "GenSigSendType" SG_ 3221225472 EPB_I_LAMP 0;
BA_ "GenSigSendType" SG_ 3221225472 EPB_F_LAMP 0;
BA_ "GenSigSendType" SG_ 3221225472 EPB_ALARM 0;
BA_ "GenSigSendType" SG_ 3221225472 EPB_CLU 0;
BA_ "GenSigSendType" SG_ 3221225472 CF_HDA_InfoDisplay 0;
BA_ "GenSigSendType" SG_ 3221225472 CF_HDA_Mode 0;
BA_ "GenSigSendType" SG_ 3221225472 CF_HDA_Opt_USM 0;
BA_ "GenSigSendType" SG_ 3221225472 CF_HDA_AutoSetSpdUpdate 0;
BA_ "GenSigSendType" SG_ 3221225472 CF_HDA_LFA_Wrn_Snd 0;
BA_ "GenSigSendType" SG_ 3221225472 CF_HDA_LFA_SymbolState 0;
BA_ "GenSigSendType" SG_ 3221225472 CF_LFA_Opt_USM 0;
BA_ "GenSigSendType" SG_ 3221225472 AutoSetSpdEnable 0;
BA_ "GenSigSendType" SG_ 3221225472 CF_LKA_LaneRecogState 0;
BA_ "GenSigSendType" SG_ 3221225472 CF_LKA_SysState 0;
BA_ "GenSigSendType" SG_ 3221225472 CF_LKA_SysWarning 0;
BA_ "GenSigSendType" SG_ 3221225472 CF_LKA_LHWarning 0;
BA_ "GenSigSendType" SG_ 3221225472 CF_LKA_RHWarning 0;
BA_ "GenSigSendType" SG_ 3221225472 CF_HBA_Lamp 0;
BA_ "GenSigSendType" SG_ 3221225472 CF_HBA_SysState 0;
BA_ "GenSigSendType" SG_ 3221225472 CF_LKA_USM_Mode 0;
BA_ "GenSigSendType" SG_ 3221225472 CF_LKA_SymbolState 0;
BA_ "GenSigSendType" SG_ 3221225472 CF_LKA_Opt_USM 0;
BA_ "GenSigSendType" SG_ 3221225472 CF_FCA_LO_Warning 0;
BA_ "GenSigSendType" SG_ 3221225472 CF_HBA_Opt_USM 0;
BA_ "GenSigSendType" SG_ 3221225472 CF_DAW_Status 0;
BA_ "GenSigSendType" SG_ 3221225472 CF_DAW_TimeReset 0;
BA_ "GenSigSendType" SG_ 3221225472 CF_DAW_Opt_USM_NEW 0;
BA_ "GenSigSendType" SG_ 3221225472 CF_DAW_Warn 0;
BA_ "GenSigSendType" SG_ 3221225472 CF_LeadVehDptAlert_Display 0;
BA_ "GenSigSendType" SG_ 3221225472 CF_ISLW_Opt_USM 0;
BA_ "GenSigSendType" SG_ 3221225472 CF_LeadVehDptAlert_USM 0;
BA_ "GenSigSendType" SG_ 3221225472 POS_FL_W_LAMP 0;
BA_ "GenSigSendType" SG_ 3221225472 POS_FR_W_LAMP 0;
BA_ "GenSigSendType" SG_ 3221225472 POS_RL_W_LAMP 0;
BA_ "GenSigSendType" SG_ 3221225472 POS_RR_W_LAMP 0;
BA_ "GenSigSendType" SG_ 3221225472 STATUS_TPMS 0;
BA_ "GenSigSendType" SG_ 3221225472 UNIT 0;
BA_ "GenSigSendType" SG_ 3221225472 PRESSURE_FL 0;
BA_ "GenSigSendType" SG_ 3221225472 PRESSURE_FR 0;
BA_ "GenSigSendType" SG_ 3221225472 PRESSURE_RL 0;
BA_ "GenSigSendType" SG_ 3221225472 PRESSURE_RR 0;
BA_ "GenSigSendType" SG_ 3221225472 TPMS_W_LAMP 0;
BA_ "GenSigSendType" SG_ 3221225472 TREAD_W_LAMP 0;
BA_ "GenSigSendType" SG_ 1998 DIAG_RSP 1;
BA_ "GenSigSendType" SG_ 1419 CF_BCW_Stat 0;
BA_ "GenSigSendType" SG_ 1419 CF_RCCW_Stat 0;
BA_ "GenSigSendType" SG_ 1419 CF_FR_SndWan 0;
BA_ "GenSigSendType" SG_ 1419 CF_FL_SndWan 0;
BA_ "GenSigSendType" SG_ 1419 CF_RR_SndWan 0;
BA_ "GenSigSendType" SG_ 1419 CF_RL_SndWan 0;
BA_ "GenSigSendType" SG_ 1164 CF_BCW_DrvSetState 5;
BA_ "GenSigSendType" SG_ 1107 CR_Fatc_OutTempSns 0;
BA_ "GenSigStartValue" SG_ 1107 CR_Fatc_OutTempSns 510;
BA_ "GenSigSendType" SG_ 1107 CR_Fatc_OutTemp 0;
BA_ "GenSigSendType" SG_ 1384 L_MIL 0;
BA_ "GenSigSendType" SG_ 1384 CF_Tcu_DriWarn1 0;
BA_ "GenSigSendType" SG_ 1384 CF_Tcu_DriWarn2 0;
BA_ "GenSigSendType" SG_ 1384 CF_Tcu_GSel_BlinkReq 0;
BA_ "GenSigSendType" SG_ 1384 CF_Tcu_SmartShift_Inf 0;
BA_ "GenSigSendType" SG_ 1384 CF_Tcu_DrivingModeDisp 0;
BA_ "GenSigSendType" SG_ 1384 BAT_SOC 0;
BA_ "GenSigSendType" SG_ 1384 CF_Tcu_DriWarn3 0;
BA_ "GenSigSendType" SG_ 1384 Bat_dischrg 0;
BA_ "GenSigSendType" SG_ 1384 CF_Tcu_SiCluster 0;
BA_ "GenSigSendType" SG_ 1394 HILL_HOLD_WARNING 0;
BA_ "GenSigSendType" SG_ 1394 Clutch_Burst_Warning 0;
BA_ "GenSigSendType" SG_ 1394 Vehicle_Stop_Time 0;
BA_ "GenSigSendType" SG_ 870 N 0;
BA_ "GenSigSendType" SG_ 870 F_N_ENG 0;
BA_ "GenSigSendType" SG_ 871 SLD_VS 0;
BA_ "GenSigSendType" SG_ 871 CF_Ems_OilChg 0;
BA_ "GenSigSendType" SG_ 871 CF_Ems_IsgStat 0;
BA_ "GenSigSendType" SG_ 871 CF_Ems_IsgStat2 0;
BA_ "GenSigSendType" SG_ 871 CF_Ems_UpTarGr 0;
BA_ "GenSigSendType" SG_ 871 CF_Ems_DownTarGr 0;
BA_ "GenSigSendType" SG_ 871 G_SEL_DISP 0;
BA_ "GenSigStartValue" SG_ 871 G_SEL_DISP 9;
BA_ "GenSigSendType" SG_ 871 CF_Ems_SldAct 0;
BA_ "GenSigSendType" SG_ 871 CF_Ems_DesCurGr 0;
BA_ "GenSigSendType" SG_ 871 GEAR_TYPE 0;
BA_ "GenSigSendType" SG_ 871 CF_Ems_IsgBuz 0;
BA_ "GenSigSendType" SG_ 872 VS_TCU 0;
BA_ "GenSigSendType" SG_ 872 VS_TCU_DECIMAL 0;
BA_ "GenSigSendType" SG_ 872 CF_Tcu_TarGr 0;
BA_ "GenSigSendType" SG_ 872 TCU_RPM_Cluster 0;
BA_ "GenSigSendType" SG_ 872 TCU_RPM_Flag 0;
BA_ "GenSigSendType" SG_ 872 TCU_TYPE 0;
BA_ "GenSigSendType" SG_ 872 CF_Tcu_TarGr_SS 0;
BA_ "GenSigSendType" SG_ 872 CF_Tcu_TarGr_Conf 0;
BA_ "GenSigSendType" SG_ 854 FCO 0;
BA_ "GenSigSendType" SG_ 576 G_SEL_DISP_eClutch 0;
BA_ "GenSigStartValue" SG_ 576 G_SEL_DISP_eClutch 9;
BA_ "GenSigSendType" SG_ 1225 CF_TCU_AvgCltTemp 0;
BA_ "GenSigSendType" SG_ 1040 CF_Gway_DrLockSoundRValue 5;
BA_ "GenSigSendType" SG_ 1040 CF_Gway_EscortHLRValue 5;
BA_ "GenSigSendType" SG_ 1040 CF_Gway_ADrLRValue 5;
BA_ "GenSigSendType" SG_ 1040 CF_Gway_ADrURValue 5;
BA_ "GenSigSendType" SG_ 1040 CF_Gway_WlightRValue 5;
BA_ "GenSigSendType" SG_ 1040 CF_Gway_OTTurnRValue 5;
BA_ "GenSigSendType" SG_ 1040 CF_Gway_HAnBRValue 5;
BA_ "GenSigSendType" SG_ 1040 CF_Gway_MoodLpRValue 5;
BA_ "GenSigSendType" SG_ 1040 CF_Gway_RearWiperRValue 5;
BA_ "GenSigSendType" SG_ 1040 CF_Gway_PasSpkrLvRValue 5;
BA_ "GenSigSendType" SG_ 1040 CF_Gway_WPCRValue 5;
BA_ "GenSigSendType" SG_ 1040 CF_Gway_PTGMRValue 5;
BA_ "GenSigSendType" SG_ 1040 CF_Gway_TTUnlockRValue 5;
BA_ "GenSigSendType" SG_ 1042 CF_Gway_AFoldRValue 5;
BA_ "GenSigSendType" SG_ 1042 CF_Gway_WALRValue 5;
BA_ "GenSigSendType" SG_ 1345 CF_Gway_IGNSw 5;
BA_ "GenSigSendType" SG_ 1345 CF_Gway_RKECmd 5;
BA_ "GenSigSendType" SG_ 1345 CF_Gway_DrvDrSw 5;
BA_ "GenSigSendType" SG_ 1345 CF_Gway_TrunkTgSw 5;
BA_ "GenSigSendType" SG_ 1345 CF_Gway_SMKOption 5;
BA_ "GenSigSendType" SG_ 1345 CF_Gway_HoodSw 5;
BA_ "GenSigSendType" SG_ 1345 CF_Gway_TurnSigLh 5;
BA_ "GenSigSendType" SG_ 1345 CF_Gway_WiperIntT 5;
BA_ "GenSigSendType" SG_ 1345 CF_Gway_HeadLampLow 5;
BA_ "GenSigSendType" SG_ 1345 CF_Gway_HeadLampHigh 5;
BA_ "GenSigSendType" SG_ 1345 CF_Gway_AstDrSw 5;
BA_ "GenSigSendType" SG_ 1345 CF_Gway_LightSwState 5;
BA_ "GenSigSendType" SG_ 1345 CF_Gway_Frt_Fog_Act 5;
BA_ "GenSigSendType" SG_ 1345 CF_Gway_DriveTypeOption 5;
BA_ "GenSigSendType" SG_ 1345 CF_Gway_PassiveAccessLock 5;
BA_ "GenSigSendType" SG_ 1345 CF_Gway_PassiveAccessUnlock 5;
BA_ "GenSigSendType" SG_ 1345 CF_Gway_InhibitRMT 5;
BA_ "GenSigSendType" SG_ 1345 CF_Gway_RainSnsOption 5;
BA_ "GenSigSendType" SG_ 1345 C_SunRoofOpenState 5;
BA_ "GenSigSendType" SG_ 1345 CF_Gway_ParkBrakeSw 5;
BA_ "GenSigSendType" SG_ 1345 CF_Gway_TurnSigRh 5;
BA_ "GenSigSendType" SG_ 1363 CF_Gway_ExtTailAct 5;
BA_ "GenSigSendType" SG_ 1363 CF_Gway_AutoLightValue 5;
BA_ "GenSigSendType" SG_ 1363 CF_Gway_BrakeFluidSw 5;
BA_ "GenSigSendType" SG_ 1363 CF_Gway_ICUPowerAutoCutMode 5;
BA_ "GenSigStartValue" SG_ 1363 CF_Gway_ICUPowerAutoCutMode 2;
BA_ "GenSigSendType" SG_ 1363 CF_Gway_AvTail 5;
BA_ "GenSigStartValue" SG_ 1363 CF_Gway_AvTail 1;
BA_ "GenSigSendType" SG_ 1363 CF_Gway_RearFogAct 5;
BA_ "GenSigSendType" SG_ 1363 CF_Gway_RRDrSw 5;
BA_ "GenSigSendType" SG_ 1363 CF_Gway_RLDrSw 5;
BA_ "GenSigSendType" SG_ 1363 CF_Gway_ESCLFailWarn 5;
BA_ "GenSigSendType" SG_ 1363 CF_Gway_ESCLNotLockedWarn 5;
BA_ "GenSigSendType" SG_ 1363 CF_Gway_ESCLNotUnlockWarn 5;
BA_ "GenSigSendType" SG_ 1363 CF_Gway_IDoutWarn 5;
BA_ "GenSigSendType" SG_ 1363 CF_Gway_ImmoLp 5;
BA_ "GenSigSendType" SG_ 1363 CF_Gway_VehicleNotPWarn 5;
BA_ "GenSigSendType" SG_ 1363 CF_Gway_DeactivationWarn 5;
BA_ "GenSigSendType" SG_ 1363 CF_Gway_KeyBATDischargeWarn 5;
BA_ "GenSigSendType" SG_ 1363 CF_Gway_SSBWarn 5;
BA_ "GenSigSendType" SG_ 1363 CF_Gway_SMKRKECmd 5;
BA_ "GenSigSendType" SG_ 1363 CF_Gway_KeyoutLp 5;
BA_ "GenSigSendType" SG_ 1363 CF_Gway_SMKDispWarn 5;
BA_ "GenSigSendType" SG_ 1363 CF_Gway_WngBuz 5;
BA_ "GenSigSendType" SG_ 1312 CF_Gway_AccINDforCLU 0;
BA_ "GenSigSendType" SG_ 1369 CF_Gway_WiperSwState 5;
BA_ "GenSigSendType" SG_ 1369 CF_Gway_DrvSeatBeltIND 5;
BA_ "GenSigSendType" SG_ 1369 CF_Gway_RrWiperSwState 5;
BA_ "GenSigSendType" SG_ 1369 CF_Gway_WPCWarning 5;
BA_ "GenSigSendType" SG_ 1369 CF_Gway_SeatBeltWngBuz 5;
BA_ "GenSigSendType" SG_ 1369 CF_Gway_AstSeatBeltIND 5;
BA_ "GenSigSendType" SG_ 127 C_StopLampLhOpenSts 5;
BA_ "GenSigSendType" SG_ 127 C_StopLampRhOpenSts 5;
BA_ "GenSigSendType" SG_ 127 C_HMSLOpenSts 5;
BA_ "GenSigSendType" SG_ 127 C_HLampLowLhOpenSts 5;
BA_ "GenSigSendType" SG_ 127 C_HLampLowRhOpenSts 5;
BA_ "GenSigSendType" SG_ 127 C_HLampHighLhOpenSts 5;
BA_ "GenSigSendType" SG_ 127 C_HLampHighRhOpenSts 5;
BA_ "GenSigSendType" SG_ 127 C_DRLLampLhOpenSts 5;
BA_ "GenSigSendType" SG_ 127 C_DRLLampRhOpenSts 5;
BA_ "GenSigSendType" SG_ 127 C_RearFOGLhOpenSts 5;
BA_ "GenSigSendType" SG_ 127 C_RearFOGRhOpenSts 5;
BA_ "GenSigSendType" SG_ 127 C_FrontFOGLhOpenSts 5;
BA_ "GenSigSendType" SG_ 127 C_FrontFOGRhOpenSts 5;
BA_ "GenSigSendType" SG_ 127 C_RearTSIGLhOpenSts 5;
BA_ "GenSigSendType" SG_ 127 C_RearTSIGRhOpenSts 5;
BA_ "GenSigSendType" SG_ 127 C_FrontTSIGLhOpenSts 5;
BA_ "GenSigSendType" SG_ 127 C_FrontTSIGRhOpenSts 5;
BA_ "GenSigSendType" SG_ 127 C_SBendingLhOpenSts 5;
BA_ "GenSigSendType" SG_ 127 C_SBendingRhOpenSts 5;
BA_ "GenSigSendType" SG_ 127 C_HLampBifuncLhOpenSts 5;
BA_ "GenSigSendType" SG_ 127 C_HLampBifuncRhOpenSts 5;
BA_ "GenSigSendType" SG_ 127 CF_Afs_LedHLStat 5;
BA_ "GenSigSendType" SG_ 127 C_FrontEXTTailLhOpenSts 5;
BA_ "GenSigSendType" SG_ 127 C_FrontEXTTailRhOpenSts 5;
BA_ "GenSigSendType" SG_ 127 C_RearEXTTailLhOpenSts 5;
BA_ "GenSigSendType" SG_ 127 C_RearEXTTailRhOpenSts 5;
BA_ "GenSigSendType" SG_ 127 C_LicensePlateLhOpenSts 5;
BA_ "GenSigSendType" SG_ 127 C_LicensePlateRhOpenSts 5;
BA_ "GenSigSendType" SG_ 127 C_FrontFOGCorneringLpRhOpenSts 5;
BA_ "GenSigSendType" SG_ 127 C_FrontFOGCorneringLpLhOpenSts 5;
BA_ "GenSigSendType" SG_ 127 CF_Gway_MoodLpColorRValue 5;
BA_ "GenSigSendType" SG_ 127 CF_Gway_MoodLpBrightRValue 5;
BA_ "GenSigSendType" SG_ 1294 CF_Gway_BCMWarning 5;
BA_ "GenSigSendType" SG_ 1294 CF_Gway_WelcomeSysTitleOption 5;
BA_ "GenSigSendType" SG_ 1294 CF_Gway_UnlockWelcomeRValue 5;
BA_ "GenSigSendType" SG_ 1294 CF_Gway_SmartWelcomeRValue 5;
BA_ "GenSigSendType" SG_ 1294 CF_ICU_SeaWarn_Lh 5;
BA_ "GenSigSendType" SG_ 1294 CF_ICU_SeaWarn_Rh 5;
BA_ "GenSigSendType" SG_ 1294 CF_Gway_WasherFluidSw 5;
BA_ "GenSigSendType" SG_ 1265 CF_Clu_CruiseSwState 0;
BA_ "GenSigSendType" SG_ 1265 CF_Clu_CruiseSwMain 0;
BA_ "GenSigSendType" SG_ 1265 CF_Clu_SldMainSW 0;
BA_ "GenSigSendType" SG_ 1265 CF_Clu_ParityBit1 0;
BA_ "GenSigSendType" SG_ 1265 CF_Clu_VanzDecimal 0;
BA_ "GenSigSendType" SG_ 1265 CF_Clu_Vanz 0;
BA_ "GenSigSendType" SG_ 1265 CF_Clu_SPEED_UNIT 0;
BA_ "GenSigSendType" SG_ 1265 CF_Clu_RheostatLevel 0;
BA_ "GenSigSendType" SG_ 1265 CF_Clu_CluInfo 0;
BA_ "GenSigSendType" SG_ 1265 CF_Clu_AliveCnt1 0;
BA_ "GenSigSendType" SG_ 1456 CF_Clu_Odometer 0;
BA_ "GenSigSendType" SG_ 1292 CF_Clu_LowfuelWarn 0;
BA_ "GenSigSendType" SG_ 1292 CF_Clu_RefDetMod 0;
BA_ "GenSigSendType" SG_ 1292 CF_Clu_AvgFCU 0;
BA_ "GenSigSendType" SG_ 1292 CF_Clu_AvgFCI 0;
BA_ "GenSigSendType" SG_ 1292 CF_Clu_DrivingModeSwi 0;
BA_ "GenSigSendType" SG_ 1292 CF_Clu_TerrainModeSw 0;
BA_ "GenSigSendType" SG_ 1292 CF_Clu_GLOW_Stat 0;
BA_ "GenSigSendType" SG_ 1292 CF_Clu_DTE 0;
BA_ "GenSigStartValue" SG_ 1292 CF_Clu_DTE 1023;
BA_ "GenSigSendType" SG_ 1292 CF_Clu_TripUnit 0;
BA_ "GenSigSendType" SG_ 1292 CF_Clu_SWL_Stat 0;
BA_ "GenSigSendType" SG_ 1292 CF_Clu_DrivinglampStat 0;
BA_ "GenSigSendType" SG_ 1292 CF_Clu_RefuelWarn 0;
BA_ "GenSigSendType" SG_ 1292 CF_Clu_IceWarnIndStat 0;
BA_ "GenSigSendType" SG_ 1292 CF_Clu_ClusterUSM 0;
BA_ "GenSigSendType" SG_ 1292 CF_Clu_AltLStatus 0;
BA_ "GenSigSendType" SG_ 1292 CF_Clu_AliveCnt2 0;
BA_ "GenSigSendType" SG_ 1292 CF_Clu_DAWLastBreakTime 0;
BA_ "GenSigSendType" SG_ 1301 CF_Clu_ADrUNValueSet 1;
BA_ "GenSigSendType" SG_ 1301 CF_Clu_ADrLNValueSet 1;
BA_ "GenSigSendType" SG_ 1301 CF_Clu_EscortHLNValueSet 1;
BA_ "GenSigSendType" SG_ 1301 CF_Clu_DoorLSNValueSet 1;
BA_ "GenSigSendType" SG_ 1301 CF_Clu_TTUnlockNValueSet 1;
BA_ "GenSigSendType" SG_ 1301 CF_Clu_PTGMNValueSet 1;
BA_ "GenSigSendType" SG_ 1301 CF_Clu_WlightNValueSet 1;
BA_ "GenSigSendType" SG_ 1301 CF_Clu_TempUnitNValueSet 1;
BA_ "GenSigSendType" SG_ 1301 CF_Clu_MoodLpNValueSet 1;
BA_ "GenSigSendType" SG_ 1301 CF_Clu_OTTurnNValueSet 1;
BA_ "GenSigSendType" SG_ 1301 CF_Clu_AFoldNValueSet 1;
BA_ "GenSigSendType" SG_ 1301 CF_Clu_PDWSpkrLvNValueSet 1;
BA_ "GenSigSendType" SG_ 1301 CF_Clu_HAnBNValueSet 1;
BA_ "GenSigSendType" SG_ 1322 CF_Clu_VehicleSpeed 5;
BA_ "GenSigSendType" SG_ 1322 CF_Clu_InhibitP 5;
BA_ "GenSigSendType" SG_ 1322 CF_Clu_InhibitR 5;
BA_ "GenSigSendType" SG_ 1322 CF_Clu_InhibitN 5;
BA_ "GenSigSendType" SG_ 1322 CF_Clu_InhibitD 5;
BA_ "GenSigSendType" SG_ 1322 CF_Clu_LanguageInfo 5;
BA_ "GenSigSendType" SG_ 1322 CF_Clu_ClusterSound 5;
BA_ "GenSigSendType" SG_ 1322 CF_Clu_DisplaySpeed 5;
BA_ "GenSigSendType" SG_ 1322 CF_Clu_FuelDispLvl 5;
BA_ "GenSigSendType" SG_ 1307 CF_Clu_TirePressUnitNValueSet 1;
BA_ "GenSigSendType" SG_ 1307 CF_Clu_RearWiperNValueSet 1;
BA_ "GenSigSendType" SG_ 1307 CF_Clu_USMReset 1;
BA_ "GenSigSendType" SG_ 1307 CF_Gway_WPCNValueSet 1;
BA_ "GenSigSendType" SG_ 1307 CF_Clu_MoodLpBrightNValueSet 1;
BA_ "GenSigSendType" SG_ 1307 CF_Clu_ICUDeliveryModeOffReq 1;
BA_ "GenSigSendType" SG_ 764 CF_Clu_TerrainModeChange 1;
BA_ "GenSigSendType" SG_ 764 CF_Clu_UnlockWelcomeNValueSet 1;
BA_ "GenSigSendType" SG_ 764 CF_Clu_SmartWelcomeNValueSet 1;
BA_ "GenSigSendType" SG_ 764 CF_Clu_DrivinglampStatChange 1;
BA_ "GenSigSendType" SG_ 764 CF_Clu_NCC_CameraNValueSet 1;
BA_ "GenSigSendType" SG_ 1190 CF_AVN_FCANValueSet 1;
BA_ "GenSigSendType" SG_ 1190 CF_AVN_CluUSMReset 1;
BA_ "GenSigSendType" SG_ 1190 CF_AVN_SCCDrvModeNValueSet 1;
BA_ "GenSigSendType" SG_ 1190 CF_AVN_DAWModeNValueSet 1;
BA_ "GenSigSendType" SG_ 1190 CF_AVN_WarningTimingNValueSet 1;
BA_ "GenSigSendType" SG_ 1190 CF_AVN_LkaModeNValueSet 1;
BA_ "GenSigSendType" SG_ 1190 CF_AVN_HDA_NValueSet 1;
BA_ "GenSigSendType" SG_ 1190 CF_AVN_NSCCCamNValueSet 1;
BA_ "GenSigSendType" SG_ 1190 CF_AVN_NSCCCrvNValueSet 1;
BA_ "GenSigSendType" SG_ 1190 CF_AVN_ISLWNValueSet 1;
BA_ "GenSigSendType" SG_ 1190 CF_AVN_LFA_NValueSet 1;
BA_ "GenSigSendType" SG_ 1190 CF_AVN_LVDANValueSet 1;
BA_ "GenSigSendType" SG_ 1190 CF_AVN_DAWModeNValueSet_New 1;
BA_ "GenSigSendType" SG_ 1158 CF_Clu_WALNValueSet 1;
BA_ "GenSigSendType" SG_ 913 CF_Clu_PaddUpSwState 0;
BA_ "GenSigSendType" SG_ 913 CF_Clu_PaddDownSwState 0;
BA_ "GenSigSendType" SG_ 68 CR_Datc_OutTempC 5;
BA_ "GenSigSendType" SG_ 68 CR_Datc_OutTempF 5;
BA_ "GenSigSendType" SG_ 67 CF_Datc_TempDispUnit 5;
BA_ "GenSigSendType" SG_ 809 TEMP_ENG 0;
BA_ "GenSigStartValue" SG_ 809 TEMP_ENG 340;
BA_ "GenSigSendType" SG_ 608 GLOW_STAT 0;
BA_ "GenSigStartValue" SG_ 608 GLOW_STAT 1;
BA_ "GenSigSendType" SG_ 608 CRUISE_LAMP_M 0;
BA_ "GenSigSendType" SG_ 608 CRUISE_LAMP_S 0;
BA_ "GenSigSendType" SG_ 608 ENG_STAT 0;
BA_ "GenSigSendType" SG_ 1170 BAT_LAMP_STAT 0;
BA_ "GenSigSendType" SG_ 1170 CF_Ems_OPSFail 0;
BA_ "GenSigSendType" SG_ 1170 DPF_LAMP_STAT 0;
BA_ "GenSigSendType" SG_ 1170 CR_Ems_EngOilTemp 0;
BA_ "GenSigStartValue" SG_ 1170 CR_Ems_EngOilTemp 70.6666666666667;
BA_ "GenSigSendType" SG_ 1479 SCR_LEVEL_WARN_LAMP 0;
BA_ "GenSigSendType" SG_ 1479 SCR_INDUCEMENT_EXIT_COND 0;
BA_ "GenSigSendType" SG_ 1479 SCR_SYS_ERROR_WARN 0;
BA_ "GenSigSendType" SG_ 1479 SCR_REMAINING_DISTANCE 0;
BA_ "GenSigSendType" SG_ 1155 FCA_DrvSetState 5;
BA_ "GenSigStartValue" SG_ 1155 FCA_DrvSetState 2;
BA_ "GenSigSendType" SG_ 1155 FCA_USM 5;
BA_ "GenSigStartValue" SG_ 1155 FCA_USM 3;
BA_ "GenSigSendType" SG_ 897 CF_Mdps_WLmp 0;
BA_ "GenSigSendType" SG_ 1078 CF_Gway_PDWCheckSound 5;
BA_ "GenSigSendType" SG_ 1078 CF_Gway_PDWRsound 5;
BA_ "GenSigSendType" SG_ 1078 CF_Gway_PDWFsound 5;
BA_ "GenSigSendType" SG_ 1078 CF_Gway_PDWDisplayFLH 5;
BA_ "GenSigSendType" SG_ 1078 CF_Gway_PDWDisplayFCTR 5;
BA_ "GenSigSendType" SG_ 1078 CF_Gway_PDWDisplayFRH 5;
BA_ "GenSigSendType" SG_ 1078 CF_Gway_PDWDisplayRCTR 5;
BA_ "GenSigSendType" SG_ 1078 CF_Gway_PDWDisplayRLH 5;
BA_ "GenSigSendType" SG_ 1078 CF_Gway_PDWDisplayRRH 5;
BA_ "GenSigSendType" SG_ 1078 CF_Gway_PDWSystemOn 5;
BA_ "GenSigSendType" SG_ 1078 CF_Gway_PDWOption 5;
BA_ "GenSigSendType" SG_ 1056 ObjValid 0;
BA_ "GenSigSendType" SG_ 1056 MainMode_SCC 0;
BA_ "GenSigSendType" SG_ 1056 SCCInfoDisplay 0;
BA_ "GenSigSendType" SG_ 1056 VSetDis 0;
BA_ "GenSigSendType" SG_ 1056 DriverAlertDisplay 0;
BA_ "GenSigSendType" SG_ 1056 TauGapSet 0;
BA_ "GenSigSendType" SG_ 1056 NSCC_Curve_Act 0;
BA_ "GenSigSendType" SG_ 1056 NSCC_Camera_Act 0;
BA_ "GenSigSendType" SG_ 1057 FCA_Failinfo 0;
BA_ "GenSigSendType" SG_ 1057 FCA_Status 0;
BA_ "GenSigSendType" SG_ 1057 TakeOverReq 0;
BA_ "GenSigSendType" SG_ 1057 SCCFailInfo 0;
BA_ "GenSigSendType" SG_ 1057 CF_VSM_Warn 0;
BA_ "GenSigSendType" SG_ 1057 CF_VSM_Stat 0;
BA_ "GenSigSendType" SG_ 1057 SCCMode 0;
BA_ "GenSigSendType" SG_ 1057 CF_VSM_ConfMode 0;
BA_ "GenSigSendType" SG_ 1057 FCA_StopReq 0;
BA_ "GenSigSendType" SG_ 1290 SCCDrvModeRValue 5;
BA_ "GenSigStartValue" SG_ 1290 SCCDrvModeRValue 2;
BA_ "GenSigSendType" SG_ 1290 NSCC_Zone_USM 5;
BA_ "GenSigSendType" SG_ 1290 NSCC_Curve_USM 5;
BA_ "GenSigSendType" SG_ 905 SCCMode2 0;
BA_ "GenSigSendType" SG_ 905 ObjGap 0;
BA_ "GenSigSendType" SG_ 1287 ABS_W_LAMP 0;
BA_ "GenSigSendType" SG_ 1287 TCS_OFF_LAMP 0;
BA_ "GenSigSendType" SG_ 1287 TCS_LAMP 0;
BA_ "GenSigSendType" SG_ 1287 ESC_Off_Step 0;
BA_ "GenSigSendType" SG_ 1287 AVH_CLU 0;
BA_ "GenSigSendType" SG_ 1287 EBD_W_LAMP 0;
BA_ "GenSigSendType" SG_ 1287 AVH_LAMP 0;
BA_ "GenSigSendType" SG_ 1287 AVH_ALARM 0;
BA_ "GenSigSendType" SG_ 354 Cluster_Engine_RPM 0;
BA_ "GenSigSendType" SG_ 354 Cluster_Engine_RPM_Flag 0;
BA_ "GenSigSendType" SG_ 902 WHL_SPD_FL 0;
BA_ "GenSigSendType" SG_ 902 WHL_SPD_FR 0;
BA_ "GenSigSendType" SG_ 902 WHL_SPD_RL 0;
BA_ "GenSigSendType" SG_ 902 WHL_SPD_RR 0;
VAL_ 3221225472 CF_SWL_Ind 0 "Warning Lamp on0x1:Warning Lamp off0x2:Warning Lamp flash0x3:Not used" ;
VAL_ 3221225472 EPB_I_LAMP 0 "Release State EPB AVH0x1:Apply State EPB0x2:Dynamic Braking EPB or Driver Action Requested" ;
VAL_ 3221225472 EPB_F_LAMP 0 "No failure0x1:Failure detected or in diagnosis mode0x2:EOL configuration not done or Emergency released0x3:Reserved" ;
VAL_ 3221225472 EPB_ALARM 0 "Off0x1:Comfortable tone Sound once0x2:Uncomfortable tone0x3:Reserved" ;
VAL_ 3221225472 EPB_CLU 0 "Off0x1:EPB is in maintenance mode0x2:Driver tries to DAR but safety condition is not satisfied0x3:EPB applies by ESC request0x4:Driver tries to DAR but safety condition is not satisfied for China" ;
VAL_ 3221225472 CF_HDA_InfoDisplay 0 "no popup0x1:system start popup0x2:system auto disengaged popup by highway off0x3:system Fail popupLFA0x4:system Fail popupHDA0x5:Handsoff pop up0x6:Handsoff pop up w sound0x7:System Automatic off" ;
VAL_ 3221225472 CF_HDA_Mode 0 "OFF0x1:Ready0x2:Active0x3:Reserved" ;
VAL_ 3221225472 CF_HDA_Opt_USM 0 "Not Applied0x1:Function Off0x2:Function On0x3:Invalid Fail" ;
VAL_ 3221225472 CF_HDA_AutoSetSpdUpdate 0 "Auto Set Speed Update OFF0x1:Auto Set Speed Update ON" ;
VAL_ 3221225472 CF_HDA_LFA_Wrn_Snd 0 "Off0x1:Additional Warning Sound" ;
VAL_ 3221225472 CF_HDA_LFA_SymbolState 0 "Off0x1:Gray0x2:Green0x3:Green blink" ;
VAL_ 3221225472 CF_LFA_Opt_USM 0 "Not Applied0x1:Function Off0x2:Function On0x3:Invalid Fail" ;
VAL_ 3221225472 AutoSetSpdEnable 0 "Auto Set Speed OFF0x1:Auto Set Speed ON" ;
VAL_ 3221225472 CF_LKA_LaneRecogState 0 "Not Recognition0x1:Left Lane Recognition0x2:Right Lane Recognition0x3:Full Lane Recognition" ;
VAL_ 3221225472 CF_LKA_SysState 0 "System OFF0x1:Low Vehicle Speed0x2:System Unavailable0x3:MDPS Control_Full Lane Recognized0x4:Full Lane Recognized0x5:Left Line Recognized0x6:Right Line Recognized0x7:MDPS Control_Left Line Recognized0x8:MDPS Control_Right Line Recognized0xE:System Not Cal" ;
VAL_ 3221225472 CF_LKA_SysWarning 0 "No Info0x4:HandsOff Warning10x5:HandsOff Warning20x9:System Automatic off0xF:System Fail" ;
VAL_ 3221225472 CF_LKA_LHWarning 0 "No Warning0x1:HAPTIC Warning and Acoustic Warning and Display0x2:Acoustic Warning and Display" ;
VAL_ 3221225472 CF_LKA_RHWarning 0 "No Warning0x1:HAPTIC Warning and Acoustic Warning and Display0x2:Acoustic Warning and Display" ;
VAL_ 3221225472 CF_HBA_Lamp 0 "HBA Indicator Lamp Off0x1:HBA Indicator Lamp On" ;
VAL_ 3221225472 CF_HBA_SysState 0 "Default Disable0x1:HBA Enable  High Beam Off0x2:HBA Enable  High Beam On0x7:System Fail" ;
VAL_ 3221225472 CF_LKA_USM_Mode 0 "NONE0x1:LKA 1 Mode0x2:LKA 2 Mode0x3:LDW" ;
VAL_ 3221225472 CF_LKA_SymbolState 0 "Off0x1:White On0x2:Green On0x3:Green Blink0x4:Orange On0x5:Orange Blink0x6:Orange ON Regulation0x7:White Blink" ;
VAL_ 3221225472 CF_LKA_Opt_USM 0 "None LKALDW Option0x1:LDW0x2:LKA0x3:ACTIVE LKA0x4:LDW Only None LKA0x5:LDW only OFF None LKA0x6:LDWLKA OFF0x7:Invalid" ;
VAL_ 3221225472 CF_FCA_LO_Warning 0 "OFFdefault0x1:Left Warning0x2:Right Warning0x3:Reserved" ;
VAL_ 3221225472 CF_HBA_Opt_USM 0 "None HBA Option Default0x1:HBA Function Off0x2:HBA Function On0x3:Invalid Fail" ;
VAL_ 3221225472 CF_DAW_Status 0 "System OFF0x1:Attention Level  10x2:Attention Level  20x3:Attention Level  30x4:Attention Level  40x5:Attention Level  50x6:Reserved0x7:Reserved0x8:Reserved0x9:Reserved0xA:Reserved0xB:Reserved0xC:Reserved0xD:Reserved0xE:System Standby0xF:System Fail" ;
VAL_ 3221225472 CF_DAW_TimeReset 0 "No Signal0x1:Time Reset" ;
VAL_ 3221225472 CF_DAW_Opt_USM_NEW 0 "None DAW OptionDefault0x1:System OFF0x2:System ON0x3:Invalid" ;
VAL_ 3221225472 CF_DAW_Warn 0 "No Warning0x1:Rest Recommend Warning0x2:Reserved0x3:Reserved" ;
VAL_ 3221225472 CF_LeadVehDptAlert_Display 0 "Default0x1:Display Lead Vehicle Departure Alert0x2:Reserved0x3:Invalid" ;
VAL_ 3221225472 CF_ISLW_Opt_USM 0 "None ISLW Option default0x1:System Disable by USM0x2:System Enable by USM0x3:Invalid" ;
VAL_ 3221225472 CF_LeadVehDptAlert_USM 0 "No Option default0x1:Off0x2:On0x3:Invalid" ;
VAL_ 3221225472 POS_FL_W_LAMP 0 "FL POSITION Warning lamp OFF0x1:FL POSITION Warning lamp ON" ;
VAL_ 3221225472 POS_FR_W_LAMP 0 "FR POSITION Warning lamp OFF0x1:FR POSITION Warning lamp ON" ;
VAL_ 3221225472 POS_RL_W_LAMP 0 "RL POSITION Warning lamp OFF0x1:RL POSITION Warning lamp ON" ;
VAL_ 3221225472 POS_RR_W_LAMP 0 "RR POSITION Warning lamp OFF0x1:RR POSITION Warning lamp ON" ;
VAL_ 3221225472 STATUS_TPMS 0 "inactive0x1:active0x2:Nodisplay the Tire Pressure0x3:Indirect TPMS with set switch0x4:Indirect TPMS with USM set0x5:reserved0x6:reserved0x7:reserved" ;
VAL_ 3221225472 UNIT 0 "psi0x1:kpa0x2:bar0x3:reserved" ;
VAL_ 3221225472 TPMS_W_LAMP 0 "TPMS Malfunction Warning lamp OFF0x1:TPMS Malfunction Warning lamp ON0x2:TPMS Malfunction Warning lamp BLINKING2Hz0x3:Reserved" ;
VAL_ 3221225472 TREAD_W_LAMP 0 "TREAD Warning lamp OFF0x1:TREAD Warning lamp ON0x2:TREAD Warning lamp BLINKING2Hz0x3:Reserved" ;
VAL_ 1419 CF_BCW_Stat 0 "System is Off0x1:System Passive0x2:System Active0x3:System Failure0x4:System Blockage0x5:Reserved0x6:System minor failure" ;
VAL_ 1419 CF_RCCW_Stat 0 "RCCW is Off0x1:RCCW Passive0x2:RCCW Active0x3:RCCW Failure0x4:RCCW Blockage0x5:Reserved0x6:RCCW Minor Failure" ;
VAL_ 1419 CF_FR_SndWan 0 "Speaker is Off0x1:Speaker On" ;
VAL_ 1419 CF_FL_SndWan 0 "Speaker is Off0x1:Speaker On" ;
VAL_ 1419 CF_RR_SndWan 0 "Speaker is Off0x1:Speaker On" ;
VAL_ 1419 CF_RL_SndWan 0 "Speaker is Off0x1:Speaker On" ;
VAL_ 1164 CF_BCW_DrvSetState 0 "Default0x1:Late0x2:Normal0x30x6:Reserved0x7:Invalid" ;
VAL_ 1384 L_MIL 0 "Check Engine lamp OFF0x1:Check Engine lamp ON" ;
VAL_ 1384 CF_Tcu_DriWarn2 0 "Normal Display0x1:Clutch OFF0x2:NoneEOL0x3:Not Used" ;
VAL_ 1384 CF_Tcu_GSel_BlinkReq 0 "No blink0x1:Reqeust lamp blinking" ;
VAL_ 1384 CF_Tcu_SmartShift_Inf 0 "Non Smartshift0x1:Smartshift Applied" ;
VAL_ 1384 CF_Tcu_DrivingModeDisp 0 "Inactive0x1:Normal0x2:Eco0x3:Eco0x4:Sport0x5:Sport0x6:Snow0x7:Reserved" ;
VAL_ 1384 CF_Tcu_DriWarn3 0 "Normal0x1:Warning message30x2:Warning message40x3:Reserve" ;
VAL_ 1384 CF_Tcu_SiCluster 0 "Invalid0x1:Step 10x2:Step 20x3:Step 30x4:Step 40x5:Step 50x6:Step 60x7:Step 70x8:Step 80x9:Step 90xA:Step 100xB:Step 110xC:Step 120xD:Step 130xE:Step 140xF:Step 150x10:Step 160x11:Step 170x12:Step 180x13:Step 190x14:Step 200x15:Step 210x16:Step 220x17:Step" ;
VAL_ 870 F_N_ENG 0 "No error0x1:Engine speed sensor defective" ;
VAL_ 871 CF_Ems_OilChg 0 "OIL LEVEL LAMP Off0x1:OIL LEVEL LAMP On" ;
VAL_ 871 CF_Ems_IsgStat 0 "ISG is not operatingNormal engine operating without ISG0x1:Idle stop is activatedIdle is stopped by ECU during driving0x2:Automatically started by ECU Engine is automatically started by ECU regardless drivers volition during idle stop becau" ;
VAL_ 871 CF_Ems_IsgStat2 0 "Default0x1:The condition for notactivated battery sensor Except EOL condition0x2:In Auto Start status when rapidly accelerating before complete gear shift Economy ISG Only" ;
VAL_ 871 CF_Ems_UpTarGr 0 "Gear Shiftup Display Off0x1:Gear Shiftup Display On" ;
VAL_ 871 CF_Ems_DownTarGr 0 "Gear Shiftdown Display Off0x1:Gear Shiftdown Display On" ;
VAL_ 871 G_SEL_DISP 0 "P0x1:L0x2:20x3:30x4:DS Mode0x5:D0x6:N0x7:R0x8:sports mode  manual shift  paddle shift0x9:Not Display at Cluster0xA:SubRom Communication0xB:SubRom Communication Error0xC:Paddle shift Dposition0xD:Reserved0xE:Intermediate Position0xF:fault" ;
VAL_ 871 CF_Ems_SldAct 0 "Speed limiter function is not active0x1:Speed limiter function is active" ;
VAL_ 871 CF_Ems_DesCurGr 0 "No display0x1:Gear Position 1 display0x2:Gear Position 2 display0x3:Gear Position 3 display0x4:Gear Position 4 display0x5:Gear Position 5 display0x6:Gear Position 6 display0x7:Gear Position 7 display0x8:Gear Position 8 display0x9:Gear Position 9 display0xA" ;
VAL_ 871 GEAR_TYPE 0 "3  Speed AT or DCT0x4:4  Speed AT or DCT0x5:5  Speed AT or DCT0x6:6  Speed AT or DCT0x7:7  Speed AT or DCT0x8:8  Speed AT or DCT" ;
VAL_ 871 CF_Ems_IsgBuz 0 "Initial Value0x1:Request buzzer ON" ;
VAL_ 872 CF_Tcu_TarGr 0 "if N or P are detected no frictional connection0x1:1st speed0x2:2nd speed0x3:3rd speed0x4:4th speed0x5:5th speed0x6:6th speed0x7:7th speed0x8:8th speed0xE:Reverse speed" ;
VAL_ 872 TCU_TYPE 0 "Reserved0x1:Step AT0x2:CVT0x3:DCT" ;
VAL_ 872 CF_Tcu_TarGr_SS 0 "if N or P are detected no frictional connection0x1:1st speed0x2:2nd speed0x3:3rd speed0x4:4th speed0x5:5th speed0x6:6th speed0x7:7th speed0x8:8th speed0xE:Reverse speed" ;
VAL_ 872 CF_Tcu_TarGr_Conf 0 "CF_Tcu_TarGr0x1:CF_Tcu_TarGr_SS" ;
VAL_ 576 G_SEL_DISP_eClutch 0 "N0x1:10x2:20x3:30x4:40x5:50x6:60x7:R0x9:Not Display at Cluster0xF:Unknown signal detectingshould not use on diagnosis" ;
VAL_ 1040 CF_Gway_DrLockSoundRValue 0 "Off0x1:Disable0x2:Enable0x3:Invalid" ;
VAL_ 1040 CF_Gway_EscortHLRValue 0 "Default Value0x1:Escort Off0x2:Escort On0x3:Invalid" ;
VAL_ 1040 CF_Gway_ADrLRValue 0 "Default Value0x1:Off0x2:Vehicle Speed On15km0x3:Shift Lever On0x4:Invalid" ;
VAL_ 1040 CF_Gway_ADrURValue 0 "Default0x1:Off0x2:Key Out On AllDoors0x3:Shift Lever On AllDoors0x4:Override0x5:Invalid0x6:Key Out On Driver Door0x7:Shift Lever On Driver Door" ;
VAL_ 1040 CF_Gway_WlightRValue 0 "Default Value0x1:Welcome Light Off0x2:Welcome Light On0x3:Invalid" ;
VAL_ 1040 CF_Gway_OTTurnRValue 0 "Default0x1:One Touch Turn Off0x2:3 Flashing0x3:5 Flashing0x4:7 Flashing0x5:Invalid" ;
VAL_ 1040 CF_Gway_HAnBRValue 0 "Default Value0x1:Arm Disarm Buzzer Off0x2:Arm Disarm Buzzer On0x3:Invalid" ;
VAL_ 1040 CF_Gway_MoodLpRValue 0 "Default Value0x1:Mood Lamp Off0x2:Mood Lamp On0x3:Mood Lamp Auto0x4:Invalid" ;
VAL_ 1040 CF_Gway_RearWiperRValue 0 "Default Value0x1:Rear Wiperreverse Off0x2:Rear Wiperreverse On0x3:Invalid" ;
VAL_ 1040 CF_Gway_PasSpkrLvRValue 0 "Default0x1:Level 10x2:Level 20x3:Level 30x40x6:Reserved0x7:Invalid Error Value" ;
VAL_ 1040 CF_Gway_WPCRValue 0 "Default0x1:OffDisable0x2:OnEnable0x3:Invalid" ;
VAL_ 1040 CF_Gway_PTGMRValue 0 "Default Value0x1:Power Mode0x2:Manual Mode0x3:Invalid" ;
VAL_ 1040 CF_Gway_TTUnlockRValue 0 "Default0x1:Ttunlock Off0x2:Ttunlock On0x3:Invalid" ;
VAL_ 1042 CF_Gway_AFoldRValue 0 "Default0x1:Off0x2:On0x3:Invalid" ;
VAL_ 1042 CF_Gway_WALRValue 0 "Default0x1:WAL Off0x2:WAL On0x3:Invalid" ;
VAL_ 1345 CF_Gway_IGNSw 0 "Key Off0x1:Key In0x2:ACC0x3:IGN0x4:Start0x7:BCAN signal Timeout" ;
VAL_ 1345 CF_Gway_RKECmd 0 "None0x1:Lock0x2:Unlock0x3:Panic0x4:Panic Stop0x5:TrunkOr Tail Gate0x6:Reserved0x7:Reserved" ;
VAL_ 1345 CF_Gway_DrvDrSw 0 "Close0x1:Open0x3:BCAN signal Timeout" ;
VAL_ 1345 CF_Gway_TrunkTgSw 0 "Trunk Close0x1:Trunk Open0x3:BCAN Timeout" ;
VAL_ 1345 CF_Gway_SMKOption 0 "Non SMK Option0x1:SMK Option" ;
VAL_ 1345 CF_Gway_HoodSw 0 "Hood Close0x1:Hood Open0x3:BCAN signal Timeout" ;
VAL_ 1345 CF_Gway_TurnSigLh 0 "Off0x1:On0x3:BCAN Timeout" ;
VAL_ 1345 CF_Gway_WiperIntT 0 "Step1SLOW0x1:Step20x2:Step30x3:Step40x4:Step5FAST" ;
VAL_ 1345 CF_Gway_HeadLampLow 0 "Off0x1:On" ;
VAL_ 1345 CF_Gway_HeadLampHigh 0 "Off0x1:On" ;
VAL_ 1345 CF_Gway_AstDrSw 0 "Close0x1:Open" ;
VAL_ 1345 CF_Gway_LightSwState 0 "Light Sw Off0x1:Tail Sw On0x2:HeadLamp Low Sw On0x3:AutoLight Sw On or DRL Sw On USA NonAutolight" ;
VAL_ 1345 CF_Gway_Frt_Fog_Act 0 "OFF0x1:ON" ;
VAL_ 1345 CF_Gway_DriveTypeOption 0 "LHD0x1:RHD" ;
VAL_ 1345 CF_Gway_PassiveAccessLock 0 "None0x1:Lock0x2:PassiveTrunkLock" ;
VAL_ 1345 CF_Gway_PassiveAccessUnlock 0 "None0x1:UnLock0x2:Unlock only DRV Door0x3:PIC_Key_Reminder" ;
VAL_ 1345 CF_Gway_InhibitRMT 0 "Gear_R Switch Off0x1:Gear_R Switch On0x3:BCAN signal Timeout" ;
VAL_ 1345 CF_Gway_RainSnsOption 0 "Non Rain Sensor Option0x1:Rain Sensor Option" ;
VAL_ 1345 C_SunRoofOpenState 0 "close0x1:open" ;
VAL_ 1345 CF_Gway_ParkBrakeSw 0 "Off0x1:On0x3:BCAN Timeout" ;
VAL_ 1345 CF_Gway_TurnSigRh 0 "Off0x1:On0x3:BCAN Timeout" ;
VAL_ 1363 CF_Gway_ExtTailAct 0 "Off0x1:On0x3:BCAN Timeout" ;
VAL_ 1363 CF_Gway_AutoLightValue 0 "OFF0x1:Night" ;
VAL_ 1363 CF_Gway_BrakeFluidSw 0 "Off0x1:On" ;
VAL_ 1363 CF_Gway_ICUPowerAutoCutMode 0 "Factory Mode default0x1:Dealer Mode0x2:Customer Mode0x3:Reserved  " ;
VAL_ 1363 CF_Gway_AvTail 0 "Off0x1:On" ;
VAL_ 1363 CF_Gway_RearFogAct 0 "Off0x1:On" ;
VAL_ 1363 CF_Gway_RRDrSw 0 "Close0x1:Open" ;
VAL_ 1363 CF_Gway_RLDrSw 0 "Close0x1:Open" ;
VAL_ 1363 CF_Gway_ESCLFailWarn 0 "Off0x1:On" ;
VAL_ 1363 CF_Gway_ESCLNotLockedWarn 0 "Off0x1:On" ;
VAL_ 1363 CF_Gway_ESCLNotUnlockWarn 0 "Off0x1:On" ;
VAL_ 1363 CF_Gway_IDoutWarn 0 "Off0x1:On" ;
VAL_ 1363 CF_Gway_ImmoLp 0 "Off0x1:On" ;
VAL_ 1363 CF_Gway_VehicleNotPWarn 0 "Off0x1:On" ;
VAL_ 1363 CF_Gway_DeactivationWarn 0 "Off0x1:On" ;
VAL_ 1363 CF_Gway_KeyBATDischargeWarn 0 "Off0x1:On" ;
VAL_ 1363 CF_Gway_SSBWarn 0 "Off0x1:On" ;
VAL_ 1363 CF_Gway_SMKRKECmd 0 "None0x1:Lock0x2:Unlock0x3:Trunkor Tail Gate0x4:Panic0x5:Panic Stop0x6:Two Step Unlock Warning" ;
VAL_ 1363 CF_Gway_KeyoutLp 0 "Off0x1:On" ;
VAL_ 1363 CF_Gway_SMKDispWarn 0 "Off0x1:Shift_P_Warning0x2:Key_Bat_Discharge_Warning0x3:Not_Unlocked_Warning0x4:AC_Plug_Connected_WarningEVPHEV0x5:Escl_Ecu_Fail_Warning0x6:Engine_Start_Operation_IND0x7:Auth_Fail_Warning0x8:Key_Removal_IND0x9:SMK_Lamp_Warning0xA:SSB_Warning0xB:Auth_Fail_Wa" ;
VAL_ 1363 CF_Gway_WngBuz 0 "Off0x1:SeatBelt Warning0x2:Key Operated Warning0x3:Parking Brake Warning0x4:Sun Roof Open Warning0x5:Key Learning SoundNoSMKOption0x6:ICE Warning0x7:Rear Fog Warning" ;
VAL_ 1312 CF_Gway_AccINDforCLU 0 "Cluster ACC Indicator Off0x1:Cluster ACC Indicator On" ;
VAL_ 1369 CF_Gway_WiperSwState 0 "Wiper Sw Off0x1:Wiper Int or Auto Sw On Refer to CF_Gway_RainSnsOption0x2:Wiper Low Sw On0x3:Wiper High Sw On" ;
VAL_ 1369 CF_Gway_DrvSeatBeltIND 0 "Off0x1:Blinking0x2:On" ;
VAL_ 1369 CF_Gway_RrWiperSwState 0 "Rr Wiper Sw Off0x1:Rr Wiper Low Sw On0x2:Rr Wiper High Sw On0x3:Reserved" ;
VAL_ 1369 CF_Gway_WPCWarning 0 "Off0x1:Cellphone on the pad0x2:Charging0x3:Charging complete0x4:Cellphone reminder0x50x6:Reserved0x7:Invalid" ;
VAL_ 1369 CF_Gway_SeatBeltWngBuz 0 "Off0x1:On" ;
VAL_ 1369 CF_Gway_AstSeatBeltIND 0 "Off0x1:Blinking0x2:On" ;
VAL_ 127 C_StopLampLhOpenSts 0 "Normal0x1:Open Status" ;
VAL_ 127 C_StopLampRhOpenSts 0 "Normal0x1:Open Status" ;
VAL_ 127 C_HMSLOpenSts 0 "Normal0x1:Open Status" ;
VAL_ 127 C_HLampLowLhOpenSts 0 "Normal0x1:Open Status" ;
VAL_ 127 C_HLampLowRhOpenSts 0 "Normal0x1:Open Status" ;
VAL_ 127 C_HLampHighLhOpenSts 0 "Normal0x1:Open Status" ;
VAL_ 127 C_HLampHighRhOpenSts 0 "Normal0x1:Open Status" ;
VAL_ 127 C_DRLLampLhOpenSts 0 "Normal0x1:Open Status" ;
VAL_ 127 C_DRLLampRhOpenSts 0 "Normal0x1:Open Status" ;
VAL_ 127 C_RearFOGLhOpenSts 0 "Normal0x1:Open Status" ;
VAL_ 127 C_RearFOGRhOpenSts 0 "Normal0x1:Open Status" ;
VAL_ 127 C_FrontFOGLhOpenSts 0 "Normal0x1:Open Status" ;
VAL_ 127 C_FrontFOGRhOpenSts 0 "Normal0x1:Open Status" ;
VAL_ 127 C_RearTSIGLhOpenSts 0 "Normal0x1:Open Status" ;
VAL_ 127 C_RearTSIGRhOpenSts 0 "Normal0x1:Open Status" ;
VAL_ 127 C_FrontTSIGLhOpenSts 0 "Normal0x1:Open Status" ;
VAL_ 127 C_FrontTSIGRhOpenSts 0 "Normal0x1:Open Status" ;
VAL_ 127 C_SBendingLhOpenSts 0 "Normal0x1:Open Status" ;
VAL_ 127 C_SBendingRhOpenSts 0 "Normal0x1:Open Status" ;
VAL_ 127 C_HLampBifuncLhOpenSts 0 "Normal0x1:Open Status" ;
VAL_ 127 C_HLampBifuncRhOpenSts 0 "Normal0x1:Open Status" ;
VAL_ 127 CF_Afs_LedHLStat 0 "LED Headlamp is in nornal condition0x1:Reserved0x2:LED Fail0x3:Reserved" ;
VAL_ 127 C_FrontEXTTailLhOpenSts 0 "Normal0x1:Open Status" ;
VAL_ 127 C_FrontEXTTailRhOpenSts 0 "Normal0x1:Open Status" ;
VAL_ 127 C_RearEXTTailLhOpenSts 0 "Normal0x1:Open Status" ;
VAL_ 127 C_RearEXTTailRhOpenSts 0 "Normal0x1:Open Status" ;
VAL_ 127 C_LicensePlateLhOpenSts 0 "Normal0x1:Open Status" ;
VAL_ 127 C_LicensePlateRhOpenSts 0 "Normal0x1:Open Status" ;
VAL_ 127 C_FrontFOGCorneringLpRhOpenSts 0 "Normal0x1:Open Status" ;
VAL_ 127 C_FrontFOGCorneringLpLhOpenSts 0 "Normal0x1:Open Status" ;
VAL_ 127 CF_Gway_MoodLpColorRValue 0 "Default Value0x1:color 10x2:color 20x3:color 30x4:color 40x5:color 50x6:color 60x7:color 70xF:Invalid" ;
VAL_ 127 CF_Gway_MoodLpBrightRValue 0 "Default Value0x1:Off0x2:step 10x3:step 20x4:step 30x5:step 40x6:reserved0x7:Invalid" ;
VAL_ 1294 CF_Gway_BCMWarning 0 "Off0x1:Power off warning0x2:Not p warning0x30x7:Reserved" ;
VAL_ 1294 CF_Gway_WelcomeSysTitleOption 0 "Default Value0x1:Welcome Mirror Light0x2:Welcome Mirror0x3:Welcome Light Reserved0x40x7:Reserved" ;
VAL_ 1294 CF_Gway_UnlockWelcomeRValue 0 "Default Value0x1:Off0x2:On0x3:Invalid" ;
VAL_ 1294 CF_Gway_SmartWelcomeRValue 0 "Default Value0x1:Off0x2:On0x3:Invalid" ;
VAL_ 1294 CF_ICU_SeaWarn_Lh 0 "SEA Left Warning OFF0x1:SEA Left Warning ON
0x2:Reserved0x3:Invalid" ;
VAL_ 1294 CF_ICU_SeaWarn_Rh 0 "SEA Right Warning OFF0x1:SEA Right Warning ON0x2:Reserved0x3:Invalid" ;
VAL_ 1294 CF_Gway_WasherFluidSw 0 "Off0x1:On" ;
VAL_ 1265 CF_Clu_CruiseSwState 0 "Idle Position0x1:ResumePlus0x2:SetMinus0x3:Time gap Distance SCC only0x4:ACCSCC cancel0x7:Reserved" ;
VAL_ 1265 CF_Clu_CruiseSwMain 0 "Off0x1:On" ;
VAL_ 1265 CF_Clu_SldMainSW 0 "Off0x1:On" ;
VAL_ 1265 CF_Clu_VanzDecimal 0 "00x1:01250x2:02500x3:0375" ;
VAL_ 1265 CF_Clu_SPEED_UNIT 0 "kmh0x1:MPH" ;
VAL_ 1265 CF_Clu_CluInfo 0 "Display is not applied0x1:Display is applied" ;
VAL_ 1292 CF_Clu_LowfuelWarn 0 "Low fuel Warning is off0x1:Low fuel Warning is on0x2:Not used0x3:Invalid" ;
VAL_ 1292 CF_Clu_RefDetMod 0 "Non refuel detected0x1:Refuel detected" ;
VAL_ 1292 CF_Clu_AvgFCU 0 "kmL0x1:L100km0x2:MPGUS0x3:MPGUK" ;
VAL_ 1292 CF_Clu_DrivingModeSwi 0 "Normal0x1:Sports0x2:Snow0x3:Eco" ;
VAL_ 1292 CF_Clu_TerrainModeSw 0 "Default0x1:Snow0x2:Sand0x3:Mud0x40x7:Reserved" ;
VAL_ 1292 CF_Clu_GLOW_Stat 0 "Lamp OFF0x1:Lamp On0x2:EMS message error0x3:Lamp Circuit Failure" ;
VAL_ 1292 CF_Clu_DTE 0 "0 Display  on0x10x3FE:Valid DTE 11022km0x3FF:Invalid Display  blinking 1Hz" ;
VAL_ 1292 CF_Clu_TripUnit 0 "Not Used0x1:km0x2:mile0x3:Invailid" ;
VAL_ 1292 CF_Clu_SWL_Stat 0 "Lamp OFF0x1:Lamp On0x2:Lamp Flashing0x3:ACU message error0x7:Lamp Circuit Failure" ;
VAL_ 1292 CF_Clu_DrivinglampStat 0 "Reserved0x1:Normal0x2:Eco0x3:Sport0x4:Sport0x5:Smart0x6:Individual0x7:Nmode" ;
VAL_ 1292 CF_Clu_RefuelWarn 0 "Refuel Popup is off0x1:Refuel Popup is on0x2:Reserved0x3:Invalid" ;
VAL_ 1292 CF_Clu_IceWarnIndStat 0 "Off0x1:On" ;
VAL_ 1292 CF_Clu_ClusterUSM 0 "Default0x1:Cluster not applied USM0x2:Cluster applied USM0x3:Reserved" ;
VAL_ 1292 CF_Clu_AltLStatus 0 "Off Low0x1:On Open or High" ;
VAL_ 1301 CF_Clu_ADrUNValueSet 0 "Default0x1:Off0x2:Key Out On AllDoors0x3:Shift Lever On AllDoors0x4:Override0x5:Invalid0x6:Key Out On Driver Door0x7:Shift Lever On Driver Door" ;
VAL_ 1301 CF_Clu_ADrLNValueSet 0 "Default0x1:Off0x2:Vehicle Speed On 15Km0x3:Shift Lever On0x4:Invalid" ;
VAL_ 1301 CF_Clu_EscortHLNValueSet 0 "Default Value0x1:Escort Off0x2:Escort On0x3:Invalid" ;
VAL_ 1301 CF_Clu_DoorLSNValueSet 0 "Off0x1:Disable0x2:Enable0x3:Invalid" ;
VAL_ 1301 CF_Clu_TTUnlockNValueSet 0 "Default0x1:Off0x2:On0x3:Invalid" ;
VAL_ 1301 CF_Clu_PTGMNValueSet 0 "Default0x1:Power Mode0x2:Manual Mode0x3:Invalid" ;
VAL_ 1301 CF_Clu_WlightNValueSet 0 "Default Value0x1:Welcome Light Off0x2:Welcome Light On0x3:Invalid" ;
VAL_ 1301 CF_Clu_TempUnitNValueSet 0 "Off0x1:Centigrade0x2:Fahrenheit0x3:Invalid" ;
VAL_ 1301 CF_Clu_MoodLpNValueSet 0 "Default Value0x1:Mood Lamp Off0x2:Mood Lamp On0x3:Modd Lamp Auto0x4:Invalid0x5:Reserved0x6:Reserved0x7:Reserved" ;
VAL_ 1301 CF_Clu_OTTurnNValueSet 0 "Default0x1:One Touch Turn Off0x2:3 Flashing0x3:5 Flashing0x4:7 Flashing0x5:Invalid0x6:Reserved0x7:Reserved" ;
VAL_ 1301 CF_Clu_AFoldNValueSet 0 "Default0x1:Off0x2:On0x3:Invalid" ;
VAL_ 1301 CF_Clu_PDWSpkrLvNValueSet 0 "Default0x1:Level 10x2:Level 20x3:Level 30x4:Reserved0x5:Reserved0x6:Reserved0x7:Invalid Error Value" ;
VAL_ 1301 CF_Clu_HAnBNValueSet 0 "Default0x1:Arm Disarm Buzzer Off0x2:Arm Disarm Buzzer On0x3:Invalid" ;
VAL_ 1322 CF_Clu_InhibitP 0 "Off0x1:OnP" ;
VAL_ 1322 CF_Clu_InhibitR 0 "Off0x1:OnR" ;
VAL_ 1322 CF_Clu_InhibitN 0 "Off0x1:OnN" ;
VAL_ 1322 CF_Clu_InhibitD 0 "Off0x1:OnD" ;
VAL_ 1322 CF_Clu_ClusterSound 0 "Cluster applied speaker0x1:Cluster applied buzzer" ;
VAL_ 1307 CF_Clu_TirePressUnitNValueSet 0 "Default Value0x1:psi0x2:kpa0x3:bar0x4:Reserved0x5:Reserved0x6:Reserved0x7:Invalid" ;
VAL_ 1307 CF_Clu_RearWiperNValueSet 0 "Default0x1:Rear Wiperreverse Off0x2:Rear Wiperreverse On0x3:Invalid" ;
VAL_ 1307 CF_Clu_USMReset 0 "Defualt0x1:Reset" ;
VAL_ 1307 CF_Gway_WPCNValueSet 0 "Default0x1:OffDisable0x2:OnEnable0x3:Invalid" ;
VAL_ 1307 CF_Clu_MoodLpBrightNValueSet 0 "Default0x1:Off0x2:step 10x3:step 20x4:step 30x5:step 40x6:reserved0x7:Invalid" ;
VAL_ 1307 CF_Clu_ICUDeliveryModeOffReq 0 "Default0x1:OFF Request" ;
VAL_ 764 CF_Clu_TerrainModeChange 0 "Default0x1:Snow0x2:Sand0x3:Mud0x40x6:Reserved0x7:Ready" ;
VAL_ 764 CF_Clu_UnlockWelcomeNValueSet 0 "Default Value0x1:Off0x2:On0x3:Invalid" ;
VAL_ 764 CF_Clu_SmartWelcomeNValueSet 0 "Default Value0x1:Off0x2:On0x3:Invalid" ;
VAL_ 764 CF_Clu_DrivinglampStatChange 0 "Reserved0x1:Normal0x2:Eco0x3:Sport0x4:Sport0x5:Smart0x6:Custom0x7:Nmode" ;
VAL_ 764 CF_Clu_NCC_CameraNValueSet 0 "Not Applied0x1:Function Off0x2:Function On  Manual Resume0x3:Function On  Automatic Resume0x40x6:Reserved0x7:Invalid" ;
VAL_ 1190 CF_AVN_FCANValueSet 0 "DefaultNoneFCA0x1:Off0x2:Warning0x3:Assist0x40x6:Reserved0x7:Invalid" ;
VAL_ 1190 CF_AVN_CluUSMReset 0 "Defualt0x1:Reset" ;
VAL_ 1190 CF_AVN_SCCDrvModeNValueSet 0 "Default0x1:Comfort0x2:Normal0x3:Dynamic0x40x6:Reserved0x7:Invalid" ;
VAL_ 1190 CF_AVN_DAWModeNValueSet 0 "Default0x1:Off0x2:Reserved0x3:Normal0x4:Early0x50x6:Reserved0x7:Invalid" ;
VAL_ 1190 CF_AVN_WarningTimingNValueSet 0 "Default0x1:Late0x2:Normal0x30x6:Reserved0x7:Invliad" ;
VAL_ 1190 CF_AVN_LkaModeNValueSet 0 "Default0x1:LDW mode0x2:LKA0x3:Reserved0x4:LDW only ON None LKA0x5:LDW only OFF None LKA0x6:LDWLKA OFF0x7:Invalid" ;
VAL_ 1190 CF_AVN_HDA_NValueSet 0 "Default0x1:Function Off0x2:Function On0x3:InvalidFail" ;
VAL_ 1190 CF_AVN_NSCCCamNValueSet 0 "Default0x1:Disable0x2:Enable0x3:Invalid" ;
VAL_ 1190 CF_AVN_NSCCCrvNValueSet 0 "Default0x1:Disable0x2:Enable0x3:Invalid" ;
VAL_ 1190 CF_AVN_ISLWNValueSet 0 "Default0x1:Disable0x2:Enable0x3:Invalid" ;
VAL_ 1190 CF_AVN_LFA_NValueSet 0 "Default0x1:Function Off0x2:Function On0x3:Invalid" ;
VAL_ 1190 CF_AVN_LVDANValueSet 0 "Default0x1:Off0x2:On0x3:Invalid" ;
VAL_ 1190 CF_AVN_DAWModeNValueSet_New 0 "Default0x1:Off0x2:On0x3:Invalid" ;
VAL_ 1158 CF_Clu_WALNValueSet 0 "Default0x1:Disable0x2:Enable0x3:Invalid" ;
VAL_ 913 CF_Clu_PaddUpSwState 0 "Idle position0x1:On" ;
VAL_ 913 CF_Clu_PaddDownSwState 0 "Idle position0x1:On" ;
VAL_ 68 CR_Datc_OutTempC 0 "Blank Display0x1:Blank Display0xFE:Sensor Fail    Display 0xFF:Invalid" ;
VAL_ 68 CR_Datc_OutTempF 0 "Blank Display0x1:Blank Display0xFE:Sensor Fail    Display 0xFF:Invalid" ;
VAL_ 67 CF_Datc_TempDispUnit 0 "Centigrade0x1:Fahrenheit" ;
VAL_ 608 GLOW_STAT 0 "Lamp Off0x1:Lamp On" ;
VAL_ 608 CRUISE_LAMP_M 0 "Cruise MAIN switch indication lamp turn OFF0x1:Cruise MAIN switch indication lamp turn ON" ;
VAL_ 608 CRUISE_LAMP_S 0 "Cruise SET switch indication lamp turn OFF0x1:Cruise SET switch indication lamp turn ON" ;
VAL_ 608 ENG_STAT 0 "Engine Stop0x1:Cranking0x2:Stalled0x3:Running0x4:Reserved0x5:Reserved0x6:Reserved0x7:Fault" ;
VAL_ 1170 BAT_LAMP_STAT 0 "Battery Warning Lamp OFF0x1:Battery Warning Lamp ON" ;
VAL_ 1170 CF_Ems_OPSFail 0 "Oil Pressure Warning Lamp OFF0x1:Oil Pressure Warning Lamp ON" ;
VAL_ 1170 DPF_LAMP_STAT 0 "DPF Warning Lamp OFF0x1:DPF Warning Lamp ON0x2:Reserved0x3:Reserved" ;
VAL_ 1479 SCR_LEVEL_WARN_LAMP 0 "Lamp Off0x1:Lamp ON UREA EMPTY : Amber" ;
VAL_ 1479 SCR_INDUCEMENT_EXIT_COND 0 "No display0x1:fill up correct urea AND No Restart In Mileage0x2:check the SCR system AND No Restart In Mileage0x3:No display0x4:poor quality inducement2US only0x5:service emissions system inducement2US only  " ;
VAL_ 1479 SCR_SYS_ERROR_WARN 0 "No display0x1:incorrect urea detected or incorrect AdBlue detected or incorrect reagent detected0x2:urea dosing malfunction or AdBlue dosing malfunction or reagent dosing malfunction0x3:urea dosing interruption AdBlue dosing interruption or reagent dosing " ;
VAL_ 1155 FCA_DrvSetState 0 "Default0x1:Late0x2:Normal0x3:Early0x40x6:Reserved0x7:Invalid" ;
VAL_ 1155 FCA_USM 0 "Default0x1:Off0x2:Warning0x3:Assist0x40x6:Reserved0x7:Invalid" ;
VAL_ 897 CF_Mdps_WLmp 0 "MDPS Malfunction Warning lamp OFF0x1:MDPS Malfunciton Warning lamp BLANKING2Hz0x2:MDPS Malfunction Warning lamp ON0x3:MDPS Malfunction Warning lamp BLANKING1Hz" ;
VAL_ 1078 CF_Gway_PDWCheckSound 0 "Off0x1:R_Confirm0x2:Error0x3:Reserved" ;
VAL_ 1078 CF_Gway_PDWRsound 0 "OFF No warning alarm0x1:1st warning0x2:2nd warning0x3:3rd warning" ;
VAL_ 1078 CF_Gway_PDWFsound 0 "OFF No warning alarm0x1:1st warning0x2:2nd warning0x3:3rd warning" ;
VAL_ 1078 CF_Gway_PDWDisplayFLH 0 "Off0x1:1st warning0x2:2nd warning0x3:3rd warning0x4:Error" ;
VAL_ 1078 CF_Gway_PDWDisplayFCTR 0 "Off0x1:1st warning0x2:2nd warning0x3:3rd warning0x4:Error" ;
VAL_ 1078 CF_Gway_PDWDisplayFRH 0 "Off0x1:1st warning0x2:2nd warning0x3:3rd warning0x4:Error" ;
VAL_ 1078 CF_Gway_PDWDisplayRCTR 0 "Off0x1:1st warning0x2:2nd warning0x3:3rd warning0x4:Error" ;
VAL_ 1078 CF_Gway_PDWDisplayRLH 0 "Off0x1:1st warning0x2:2nd warning0x3:3rd warning0x4:Error" ;
VAL_ 1078 CF_Gway_PDWDisplayRRH 0 "Off0x1:1st warning0x2:2nd warning0x3:3rd warning0x4:Error" ;
VAL_ 1078 CF_Gway_PDWSystemOn 0 "OFF0x1:ON0x2:reserved0x3:reserved" ;
VAL_ 1078 CF_Gway_PDWOption 0 "Non0x1:PDWR0x2:PDW0x3:reserved" ;
VAL_ 1056 ObjValid 0 "No inpath object detected0x1:Inpath object detected" ;
VAL_ 1056 MainMode_SCC 0 "OFF0x1:ON" ;
VAL_ 1056 SCCInfoDisplay 0 "0x1:Display SCC Mode0x2:Display Conventional Cruise Mode0x3:Display Object disappeared at low speed0x4:Display Available to resume acceleration control0x5:Display Front vehicle departure notice0x60x7:Reserved" ;
VAL_ 1056 DriverAlertDisplay 0 "0x1:Display SCC Disengaged0x2:Display No SCC Engage Condition0x3:Display SCC Disengaged When The Vehicle Stops" ;
VAL_ 1056 TauGapSet 0 "No time gap set0x1:1st level distance0x2:2nd level distance0x3:3rd level distance0x4:4th level distance" ;
VAL_ 1056 NSCC_Curve_Act 0 "Off0x1:Ready0x2:Act0x3:Reserved" ;
VAL_ 1056 NSCC_Camera_Act 0 "Off0x1:Ready0x2:Act0x3:Reserved" ;
VAL_ 1057 FCA_Failinfo 0 "Normal0x1:Temp Unavailable by Camera0x2:Temp Unavailable by Radar0x3:Service Required" ;
VAL_ 1057 FCA_Status 0 "Not Applied0x1:System Off0x2:System On0x3:InvaildFail" ;
VAL_ 1057 TakeOverReq 0 "No takeover request0x1:Takeover request" ;
VAL_ 1057 SCCFailInfo 0 "System without error0x1:Performance degredation0x2:System temporairy unavailable0x3:SCC Service Required" ;
VAL_ 1057 CF_VSM_Warn 0 "No warning0x1:Warning level 10x2:Warning level 20x3:Warning level 3" ;
VAL_ 1057 CF_VSM_Stat 0 "Not applicable0x1:Available0x2:Temporarily not available0x3:Permanently not available" ;
VAL_ 1057 SCCMode 0 "Off0x1:Engaged0x2:Override0x3:Shutoff" ;
VAL_ 1057 CF_VSM_ConfMode 0 "Reserved0x1:CDM Off0x2:CDM On0x3:Reserved " ;
VAL_ 1057 FCA_StopReq 0 "No request0x1:Stop control is required" ;
VAL_ 1290 SCCDrvModeRValue 0 "Default0x1:Comford Mode0x2:Normal Mode0x3:Dynamic Mode0x40x6:Reserved0x7:Invalid" ;
VAL_ 1290 NSCC_Zone_USM 0 "Default0x1:Off0x2:On0x3:Invalid" ;
VAL_ 1290 NSCC_Curve_USM 0 "Default0x1:Off0x2:On0x3:Invaild" ;
VAL_ 905 SCCMode2 0 "Off0x1:Engaged0x2:Override0x3:Shutoff0x4:Canceled" ;
VAL_ 905 ObjGap 0 "No inpath object detected0x1:Distance warning0x2:1st level object distance0x3:2nd level object distance0x4:3rd level object distance0x5:4th level object distance0x60xFF:reserved" ;
VAL_ 1287 ABS_W_LAMP 0 "ABS Warning lamp OFF0x1:ABS Warning lamp ON" ;
VAL_ 1287 TCS_OFF_LAMP 0 "TCSESC OFF SW Lamp OFF0x1:TCSESC OFF SW Lamp ON" ;
VAL_ 1287 TCS_LAMP 0 "TCSESC FunctionWarning Lamp OFF0x1:TCSESC FunctionWarning Lamp ON0x2:TCSESC FunctionWarning Lamp BLINKING2Hz0x3:Reserved" ;
VAL_ 1287 ESC_Off_Step 0 "Normal Mode0x1:Sports Mode0x2:Off Mode0x3:ESC OFF SW is defective failed" ;
VAL_ 1287 AVH_CLU 0 "AVH is off0x1:AUTO HOLD to be deactivated Press Brake Pedal0x2:Press Brake Pedal to Release AUTO HOLD0x3:AUTO HOLD cannot be activated Close Seat Belt Door Hood Trunk0x4:AUTO HOLD cannot be activated Close Seat Belt Door Hood0x5:AUTO HOLD cannot be deactiv" ;
VAL_ 1287 EBD_W_LAMP 0 "EBD Warning lamp OFF0x1:EBD Warning lamp ON" ;
VAL_ 1287 AVH_LAMP 0 "AVH Off Lamp Status0x1:AVH failure Lamp Status0x2:AVH ACTIVE Lamp Status0x3:AVH READY Lamp Status0x4:Lamp Status0x5:Lamp Status0x6:Lamp Status" ;
VAL_ 1287 AVH_ALARM 0 "No alarm0x1:On AVH Activation Vehicle is not secured and driver is still inside  comfortable tone" ;
